VERSION "dbc-export 1 2026.26.6.5"

NS_ :

BS_:

BU_: ADSP APB APP APS APSB BB BMS CC CMP CMPD CP DAS DI DIF DIR DPB EPAS3P EPAS3S EPASTP EPASTS EPBL EPBR ESP EVSE FC GTW HCML HCMR HVP IBST ICR IDB LS OCS1P ODIN PARK PCS PCS2 PLG PM PMF PMR PNCD PTC RADC RCM RCM2 RCM3 RCU SCCM SCM SCS SDCR TAS TCU TCU2 TPMS TRCM UDS UI UIS UMC USM V2G VC VCBATT VCBATT0 VCBATT1 VCBATT2 VCCC VCFRONT VCFRONT1 VCFRONT2 VCLEFT VCRIGHT VCSEAT2L VCSEAT2R VCSEC VEH

BO_ 854 DIF_alertMatrix: 8 DIF
 SG_ DIF_matrixIndex M : 0|4@1+ (1,0) [0|15] "" Vector__XXX
 SG_ DIF_a001_hwPhaseAgateDrive m0 : 4|1@1+ (1,0) [0|1] "" Vector__XXX
 SG_ DIF_a002_hwPhaseBgateDrive m0 : 5|1@1+ (1,0) [0|1] "" Vector__XXX
 SG_ DIF_a003_hwPhaseCgateDrive m0 : 6|1@1+ (1,0) [0|1] "" Vector__XXX
 SG_ DIF_a004_hwPhaseApeak m0 : 7|1@1+ (1,0) [0|1] "" Vector__XXX
 SG_ DIF_a005_hwPhaseBpeak m0 : 8|1@1+ (1,0) [0|1] "" Vector__XXX
 SG_ DIF_a006_hwPhaseCpeak m0 : 9|1@1+ (1,0) [0|1] "" Vector__XXX
 SG_ DIF_a007_statorAnomalyDetected m0 : 10|1@1+ (1,0) [0|1] "" Vector__XXX
 SG_ DIF_a008_hwEncoderA m0 : 11|1@1+ (1,0) [0|1] "" Vector__XXX
 SG_ DIF_a009_hwEncoderB m0 : 12|1@1+ (1,0) [0|1] "" Vector__XXX
 SG_ DIF_a010_unintendedReset m0 : 13|1@1+ (1,0) [0|1] "" Vector__XXX
 SG_ DIF_a011_swPowerStageNotReady m0 : 14|1@1+ (1,0) [0|1] "" Vector__XXX
 SG_ DIF_a012_hvilNotClosed m0 : 15|1@1+ (1,0) [0|1] "" Vector__XXX
 SG_ DIF_a013_eccError m0 : 16|1@1+ (1,0) [0|1] "" Vector__XXX
 SG_ DIF_a014_activeDamping m0 : 17|1@1+ (1,0) [0|1] "" Vector__XXX
 SG_ DIF_a015_mechSafeStateAnomaly m0 : 18|1@1+ (1,0) [0|1] "" Vector__XXX
 SG_ DIF_a016_safeStateApplied m0 : 19|1@1+ (1,0) [0|1] "" Vector__XXX
 SG_ DIF_a017_hwPedalMonitor m0 : 20|1@1+ (1,0) [0|1] "" Vector__XXX
 SG_ DIF_a018_hwLVSupplyUV m0 : 21|1@1+ (1,0) [0|1] "" Vector__XXX
 SG_ DIF_a020_hwMotorEncoder m0 : 23|1@1+ (1,0) [0|1] "" Vector__XXX
 SG_ DIF_a021_hwBusOV m0 : 24|1@1+ (1,0) [0|1] "" Vector__XXX
 SG_ DIF_a022_hw5vSupplyUV m0 : 25|1@1+ (1,0) [0|1] "" Vector__XXX
 SG_ DIF_a024_selfTest m0 : 27|1@1+ (1,0) [0|1] "" Vector__XXX
 SG_ DIF_a025_phaseApeak m0 : 28|1@1+ (1,0) [0|1] "" Vector__XXX
 SG_ DIF_a026_phaseBpeak m0 : 29|1@1+ (1,0) [0|1] "" Vector__XXX
 SG_ DIF_a027_phaseCpeak m0 : 30|1@1+ (1,0) [0|1] "" Vector__XXX
 SG_ DIF_a028_phaseArms m0 : 31|1@1+ (1,0) [0|1] "" Vector__XXX
 SG_ DIF_a029_phaseBrms m0 : 32|1@1+ (1,0) [0|1] "" Vector__XXX
 SG_ DIF_a030_phaseCrms m0 : 33|1@1+ (1,0) [0|1] "" Vector__XXX
 SG_ DIF_a031_phaseAcurrentOffset m0 : 34|1@1+ (1,0) [0|1] "" Vector__XXX
 SG_ DIF_a032_phaseBcurrentOffset m0 : 35|1@1+ (1,0) [0|1] "" Vector__XXX
 SG_ DIF_a033_phaseAcurrentSensor m0 : 36|1@1+ (1,0) [0|1] "" Vector__XXX
 SG_ DIF_a034_phaseBcurrentSensor m0 : 37|1@1+ (1,0) [0|1] "" Vector__XXX
 SG_ DIF_a035_phaseCurrentBalance m0 : 38|1@1+ (1,0) [0|1] "" Vector__XXX
 SG_ DIF_a036_busOV m0 : 39|1@1+ (1,0) [0|1] "" Vector__XXX
 SG_ DIF_a037_busUV m0 : 40|1@1+ (1,0) [0|1] "" Vector__XXX
 SG_ DIF_a038_busVsensor m0 : 41|1@1+ (1,0) [0|1] "" Vector__XXX
 SG_ DIF_a039_exceptionUndefinedInstr m0 : 42|1@1+ (1,0) [0|1] "" Vector__XXX
 SG_ DIF_a040_difMIA m0 : 43|1@1+ (1,0) [0|1] "" Vector__XXX
 SG_ DIF_a041_sdcMIA m0 : 44|1@1+ (1,0) [0|1] "" Vector__XXX
 SG_ DIF_a042_inletSensor m0 : 45|1@1+ (1,0) [0|1] "" Vector__XXX
 SG_ DIF_a043_outletOT m0 : 46|1@1+ (1,0) [0|1] "" Vector__XXX
 SG_ DIF_a044_outletUT m0 : 47|1@1+ (1,0) [0|1] "" Vector__XXX
 SG_ DIF_a045_outletSensor m0 : 48|1@1+ (1,0) [0|1] "" Vector__XXX
 SG_ DIF_a046_statorOT m0 : 49|1@1+ (1,0) [0|1] "" Vector__XXX
 SG_ DIF_a047_statorSensor1 m0 : 50|1@1+ (1,0) [0|1] "" Vector__XXX
 SG_ DIF_a048_statorSensor2 m0 : 51|1@1+ (1,0) [0|1] "" Vector__XXX
 SG_ DIF_a049_statorSensorDiff m0 : 52|1@1+ (1,0) [0|1] "" Vector__XXX
 SG_ DIF_a050_noStatorSensor m0 : 53|1@1+ (1,0) [0|1] "" Vector__XXX
 SG_ DIF_a052_dirMIA m0 : 55|1@1+ (1,0) [0|1] "" Vector__XXX
 SG_ DIF_a053_unexpectedLatchState m0 : 56|1@1+ (1,0) [0|1] "" Vector__XXX
 SG_ DIF_a054_driveInverterOT m0 : 57|1@1+ (1,0) [0|1] "" Vector__XXX
 SG_ DIF_a055_trqCrossCheck m0 : 58|1@1+ (1,0) [0|1] "" Vector__XXX
 SG_ DIF_a056_ambientOT m0 : 59|1@1+ (1,0) [0|1] "" Vector__XXX
 SG_ DIF_a057_ambientUT m0 : 60|1@1+ (1,0) [0|1] "" Vector__XXX
 SG_ DIF_a058_ambientSensor m0 : 61|1@1+ (1,0) [0|1] "" Vector__XXX
 SG_ DIF_a059_heatsinkOT m0 : 62|1@1+ (1,0) [0|1] "" Vector__XXX
 SG_ DIF_a060_heatsinkUT m0 : 63|1@1+ (1,0) [0|1] "" Vector__XXX
 SG_ DIF_a061_heatsinkSensor m1 : 4|1@1+ (1,0) [0|1] "" Vector__XXX
 SG_ DIF_a062_systemLimpMode m1 : 5|1@1+ (1,0) [0|1] "" Vector__XXX
 SG_ DIF_a063_bbMIA m1 : 6|1@1+ (1,0) [0|1] "" Vector__XXX
 SG_ DIF_a064_torqueIntervention m1 : 7|1@1+ (1,0) [0|1] "" Vector__XXX
 SG_ DIF_a065_canHardwareBusB m1 : 8|1@1+ (1,0) [0|1] "" Vector__XXX
 SG_ DIF_a066_canDataBusB m1 : 9|1@1+ (1,0) [0|1] "" Vector__XXX
 SG_ DIF_a067_canOverrunBusB m1 : 10|1@1+ (1,0) [0|1] "" Vector__XXX
 SG_ DIF_a069_rotorTempLimit m1 : 12|1@1+ (1,0) [0|1] "" Vector__XXX
 SG_ DIF_a070_udsTransactionInitiated m1 : 13|1@1+ (1,0) [0|1] "" Vector__XXX
 SG_ DIF_a071_busDisconnected m1 : 14|1@1+ (1,0) [0|1] "" Vector__XXX
 SG_ DIF_a072_gateDriveFaultCounter m1 : 15|1@1+ (1,0) [0|1] "" Vector__XXX
 SG_ DIF_a073_motorSpeed m1 : 16|1@1+ (1,0) [0|1] "" Vector__XXX
 SG_ DIF_a074_motorEncoder m1 : 17|1@1+ (1,0) [0|1] "" Vector__XXX
 SG_ DIF_a075_motorSpeedMismatch m1 : 18|1@1+ (1,0) [0|1] "" Vector__XXX
 SG_ DIF_a076_lvSupplyOV m1 : 19|1@1+ (1,0) [0|1] "" Vector__XXX
 SG_ DIF_a077_lvSupplyUV m1 : 20|1@1+ (1,0) [0|1] "" Vector__XXX
 SG_ DIF_a078_adcRefLow m1 : 21|1@1+ (1,0) [0|1] "" Vector__XXX
 SG_ DIF_a079_adcRefHigh m1 : 22|1@1+ (1,0) [0|1] "" Vector__XXX
 SG_ DIF_a084_eccTestData0 m1 : 27|1@1+ (1,0) [0|1] "" Vector__XXX
 SG_ DIF_d085_driveInverterBoardFailu m1 : 28|1@1+ (1,0) [0|1] "" Vector__XXX
 SG_ DIF_a086_activeDischargeOn m1 : 29|1@1+ (1,0) [0|1] "" Vector__XXX
 SG_ DIF_a087_gtwMIA m1 : 30|1@1+ (1,0) [0|1] "" Vector__XXX
 SG_ DIF_a088_uiMIA m1 : 31|1@1+ (1,0) [0|1] "" Vector__XXX
 SG_ DIF_d089_invalidTorqueCommand m1 : 32|1@1+ (1,0) [0|1] "" Vector__XXX
 SG_ DIF_a090_pmMIA m1 : 33|1@1+ (1,0) [0|1] "" Vector__XXX
 SG_ DIF_a091_espMIA m1 : 34|1@1+ (1,0) [0|1] "" Vector__XXX
 SG_ DIF_a092_bmsMIA m1 : 35|1@1+ (1,0) [0|1] "" Vector__XXX
 SG_ DIF_a093_canHardwareBusA m1 : 36|1@1+ (1,0) [0|1] "" Vector__XXX
 SG_ DIF_a094_canDataBusA m1 : 37|1@1+ (1,0) [0|1] "" Vector__XXX
 SG_ DIF_a095_canOverrunBusA m1 : 38|1@1+ (1,0) [0|1] "" Vector__XXX
 SG_ DIF_a096_memoryError m1 : 39|1@1+ (1,0) [0|1] "" Vector__XXX
 SG_ DIF_a097_eepromError m1 : 40|1@1+ (1,0) [0|1] "" Vector__XXX
 SG_ DIF_a098_intTimeTooLong m1 : 41|1@1+ (1,0) [0|1] "" Vector__XXX
 SG_ DIF_a099_threadOverrun m1 : 42|1@1+ (1,0) [0|1] "" Vector__XXX
 SG_ DIF_a100_assertion m1 : 43|1@1+ (1,0) [0|1] "" Vector__XXX
 SG_ DIF_a101_eccTestData1 m1 : 44|1@1+ (1,0) [0|1] "" Vector__XXX
 SG_ DIF_a102_exceptionPrefetchAbort m1 : 45|1@1+ (1,0) [0|1] "" Vector__XXX
 SG_ DIF_a103_lowFlow m1 : 46|1@1+ (1,0) [0|1] "" Vector__XXX
 SG_ DIF_d104_resetUnintended m1 : 47|1@1+ (1,0) [0|1] "" Vector__XXX
 SG_ DIF_d105_busVoltageSensorIssue m1 : 48|1@1+ (1,0) [0|1] "" Vector__XXX
 SG_ DIF_a106_idleTaskStarving m1 : 49|1@1+ (1,0) [0|1] "" Vector__XXX
 SG_ DIF_a107_fpgaError m1 : 50|1@1+ (1,0) [0|1] "" Vector__XXX
 SG_ DIF_a108_stateTrans m1 : 51|1@1+ (1,0) [0|1] "" Vector__XXX
 SG_ DIF_a109_ahbWriteError m1 : 52|1@1+ (1,0) [0|1] "" Vector__XXX
 SG_ DIF_a110_brakeMIA m1 : 53|1@1+ (1,0) [0|1] "" Vector__XXX
 SG_ DIF_a111_badPhaseSensorCalib m1 : 54|1@1+ (1,0) [0|1] "" Vector__XXX
 SG_ DIF_a112_noPhaseCurrent m1 : 55|1@1+ (1,0) [0|1] "" Vector__XXX
 SG_ DIF_a113_noFuncHeatsinkSensor m1 : 56|1@1+ (1,0) [0|1] "" Vector__XXX
 SG_ DIF_a114_exceptionDataAbort m1 : 57|1@1+ (1,0) [0|1] "" Vector__XXX
 SG_ DIF_a115_exceptionDataAbort2 m1 : 58|1@1+ (1,0) [0|1] "" Vector__XXX
 SG_ DIF_a116_highSpeedWearCounter m1 : 59|1@1+ (1,0) [0|1] "" Vector__XXX
 SG_ DIF_a117_diMIA m1 : 60|1@1+ (1,0) [0|1] "" Vector__XXX
 SG_ DIF_d118_oilPumpCommsLost m1 : 61|1@1+ (1,0) [0|1] "" Vector__XXX
 SG_ DIF_a119_hvpMIA m1 : 62|1@1+ (1,0) [0|1] "" Vector__XXX
 SG_ DIF_a120_hvlinkMIA m1 : 63|1@1+ (1,0) [0|1] "" Vector__XXX
 SG_ DIF_a121_motorControlRegulation m2 : 4|1@1+ (1,0) [0|1] "" Vector__XXX
 SG_ DIF_a122_highStackUsage m2 : 5|1@1+ (1,0) [0|1] "" Vector__XXX
 SG_ DIF_a123_lossMotorControl m2 : 6|1@1+ (1,0) [0|1] "" Vector__XXX
 SG_ DIF_d124_oilPumpServiceRequired m2 : 7|1@1+ (1,0) [0|1] "" Vector__XXX
 SG_ DIF_d125_currentSensorIssue m2 : 8|1@1+ (1,0) [0|1] "" Vector__XXX
 SG_ DIF_a126_limpMode m2 : 9|1@1+ (1,0) [0|1] "" Vector__XXX
 SG_ DIF_a127_gracefulPowerOff m2 : 10|1@1+ (1,0) [0|1] "" Vector__XXX
 SG_ DIF_a128_fpgaVersionMismatch m2 : 11|1@1+ (1,0) [0|1] "" Vector__XXX
 SG_ DIF_d129_oilPumpIssue m2 : 12|1@1+ (1,0) [0|1] "" Vector__XXX
 SG_ DIF_d130_positionSensorIssue m2 : 13|1@1+ (1,0) [0|1] "" Vector__XXX
 SG_ DIF_d131_currentSensorOffset m2 : 14|1@1+ (1,0) [0|1] "" Vector__XXX
 SG_ DIF_d132_busUVIssue m2 : 15|1@1+ (1,0) [0|1] "" Vector__XXX
 SG_ DIF_a133_capacitorOT m2 : 16|1@1+ (1,0) [0|1] "" Vector__XXX
 SG_ DIF_a134_wheelSpeedIrrational m2 : 17|1@1+ (1,0) [0|1] "" Vector__XXX
 SG_ DIF_d135_rotatedStator m2 : 18|1@1+ (1,0) [0|1] "" Vector__XXX
 SG_ DIF_a136_spiError m2 : 19|1@1+ (1,0) [0|1] "" Vector__XXX
 SG_ DIF_d137_currentSensorOutOfRange m2 : 20|1@1+ (1,0) [0|1] "" Vector__XXX
 SG_ DIF_d138_inverterLVPowerSupplyLo m2 : 21|1@1+ (1,0) [0|1] "" Vector__XXX
 SG_ DIF_d141_coolingSystemIssue m2 : 24|1@1+ (1,0) [0|1] "" Vector__XXX
 SG_ DIF_a142_highLashAngle m2 : 25|1@1+ (1,0) [0|1] "" Vector__XXX
 SG_ DIF_d143_wheelSpeedCorrelationIs m2 : 26|1@1+ (1,0) [0|1] "" Vector__XXX
 SG_ DIF_a144_configMismatch m2 : 27|1@1+ (1,0) [0|1] "" Vector__XXX
 SG_ DIF_a147_highTorqueWearLimit m2 : 30|1@1+ (1,0) [0|1] "" Vector__XXX
 SG_ DIF_a148_burnInCycleEnded m2 : 31|1@1+ (1,0) [0|1] "" Vector__XXX
 SG_ DIF_a149_oilPumpFailure m2 : 32|1@1+ (1,0) [0|1] "" Vector__XXX
 SG_ DIF_a150_busVD m2 : 33|1@1+ (1,0) [0|1] "" Vector__XXX
 SG_ DIF_a151_shockTorqueLimiter m2 : 34|1@1+ (1,0) [0|1] "" Vector__XXX
 SG_ DIF_a152_linError m2 : 35|1@1+ (1,0) [0|1] "" Vector__XXX
 SG_ DIF_a153_oilPumpDiagnostics m2 : 36|1@1+ (1,0) [0|1] "" Vector__XXX
 SG_ DIF_a154_resolver m2 : 37|1@1+ (1,0) [0|1] "" Vector__XXX
 SG_ DIF_a155_vcfrontMIA m2 : 38|1@1+ (1,0) [0|1] "" Vector__XXX
 SG_ DIF_a156_currentObserver m2 : 39|1@1+ (1,0) [0|1] "" Vector__XXX
 SG_ DIF_a157_rcmMIA m2 : 40|1@1+ (1,0) [0|1] "" Vector__XXX
 SG_ DIF_a158_ibstMIA m2 : 41|1@1+ (1,0) [0|1] "" Vector__XXX
 SG_ DIF_a160_busVoltageAnomaly m2 : 43|1@1+ (1,0) [0|1] "" Vector__XXX
 SG_ DIF_a161_epas3pMIA m2 : 44|1@1+ (1,0) [0|1] "" Vector__XXX
 SG_ DIF_a162_endOfLifetimeBurnIn m2 : 45|1@1+ (1,0) [0|1] "" Vector__XXX
 SG_ DIF_d163_recoverableOvercurrent m2 : 46|1@1+ (1,0) [0|1] "" Vector__XXX
 SG_ DIF_d164_firmwareConfigMismatch m2 : 47|1@1+ (1,0) [0|1] "" Vector__XXX
 SG_ DIF_d165_statorOverTemperature m2 : 48|1@1+ (1,0) [0|1] "" Vector__XXX
 SG_ DIF_d166_rotorOverTemperature m2 : 49|1@1+ (1,0) [0|1] "" Vector__XXX
 SG_ DIF_d167_tempSensorIssue m2 : 50|1@1+ (1,0) [0|1] "" Vector__XXX
 SG_ DIF_d168_clutchPerformance m2 : 51|1@1+ (1,0) [0|1] "" Vector__XXX
 SG_ DIF_d169_clutchPosition m2 : 52|1@1+ (1,0) [0|1] "" Vector__XXX
 SG_ DIF_d170_clutchFailure m2 : 53|1@1+ (1,0) [0|1] "" Vector__XXX
 SG_ DIF_a172_statorOilTempOT m2 : 55|1@1+ (1,0) [0|1] "" Vector__XXX
 SG_ DIF_a173_ascFdbkDiagnostic m2 : 56|1@1+ (1,0) [0|1] "" Vector__XXX
 SG_ DIF_a174_unitMayNotRestart m2 : 57|1@1+ (1,0) [0|1] "" Vector__XXX
 SG_ DIF_a176_safetyICFault m2 : 59|1@1+ (1,0) [0|1] "" Vector__XXX
 SG_ DIF_a177_fluxReferenceCorrected m2 : 60|1@1+ (1,0) [0|1] "" Vector__XXX
 SG_ DIF_a202_excessHeatUnavailable m3 : 25|1@1+ (1,0) [0|1] "" Vector__XXX
 SG_ DIF_a225_tmpEstPlausibility m3 : 48|1@1+ (1,0) [0|1] "" Vector__XXX
 SG_ DIF_a229_busVsensorOverCAN m3 : 52|1@1+ (1,0) [0|1] "" Vector__XXX
 SG_ DIF_a233_diMsgMissed m3 : 56|1@1+ (1,0) [0|1] "" Vector__XXX
 SG_ DIF_a234_pcsMIA m3 : 57|1@1+ (1,0) [0|1] "" Vector__XXX
 SG_ DIF_a236_tasMIA m3 : 59|1@1+ (1,0) [0|1] "" Vector__XXX
 SG_ DIF_a240_clearFusesRoutine m3 : 63|1@1+ (1,0) [0|1] "" Vector__XXX
 SG_ DIF_a241_systemThermallyLimited m4 : 4|1@1+ (1,0) [0|1] "" Vector__XXX
 SG_ DIF_a242_spinDownLearning m4 : 5|1@1+ (1,0) [0|1] "" Vector__XXX
 SG_ DIF_a243_ecuLogAvailable m4 : 6|1@1+ (1,0) [0|1] "" Vector__XXX
 SG_ DIF_a244_mechSafeStateApplied m4 : 7|1@1+ (1,0) [0|1] "" Vector__XXX
 SG_ DIF_a245_mechSafeStatePreWarn m4 : 8|1@1+ (1,0) [0|1] "" Vector__XXX
 SG_ DIF_a246_recoveryAtSpeedError m4 : 9|1@1+ (1,0) [0|1] "" Vector__XXX
 SG_ DIF_a247_rotorOffsetError m4 : 10|1@1+ (1,0) [0|1] "" Vector__XXX
 SG_ DIF_a249_highStatorTempFromResis m4 : 12|1@1+ (1,0) [0|1] "" Vector__XXX
 SG_ DIF_a250_preregulatorRail m4 : 13|1@1+ (1,0) [0|1] "" Vector__XXX
 SG_ DIF_a251_oilPumpService m4 : 14|1@1+ (1,0) [0|1] "" Vector__XXX
 SG_ DIF_a252_currentCoreFallback m4 : 15|1@1+ (1,0) [0|1] "" Vector__XXX
 SG_ DIF_a253_lvBoostedRail m4 : 16|1@1+ (1,0) [0|1] "" Vector__XXX
 SG_ DIF_a254_activeDischargeRail m4 : 17|1@1+ (1,0) [0|1] "" Vector__XXX
 SG_ DIF_a255_currentGainFallback m4 : 18|1@1+ (1,0) [0|1] "" Vector__XXX

BO_ 1879 DIF_debug: 8 DIF
 SG_ DIF_debugSelector M : 0|8@1+ (1,0) [0|255] "" Vector__XXX
 SG_ DIF_motorIA m32 : 8|16@1+ (0.1,0) [0|6553.5] "A" Vector__XXX
 SG_ DIF_motorIB m32 : 24|16@1+ (0.1,0) [0|6553.5] "A" Vector__XXX
 SG_ DIF_motorIC m32 : 40|16@1+ (0.1,0) [0|6553.5] "A" Vector__XXX
 SG_ DIF_statorIDref m33 : 8|16@1- (0.1,0) [-3276.8|3276.7] "A" Vector__XXX
 SG_ DIF_statorIDfdb m33 : 24|16@1- (0.1,0) [-3276.8|3276.7] "A" Vector__XXX
 SG_ DIF_torquePerAmp m33 : 40|16@1+ (0.0001,0) [0|6.5535] "Nm/A" Vector__XXX
 SG_ DIF_rsScale m34 : 8|8@1+ (0.01,0) [0|2.55] "scale" Vector__XXX
 SG_ DIF_statorIQref m34 : 16|16@1- (0.1,0) [-3276.8|3276.7] "A" Vector__XXX
 SG_ DIF_statorIQfdb m34 : 32|16@1- (0.1,0) [-3276.8|3276.7] "A" Vector__XXX
 SG_ DIF_motorV m34 : 48|16@1+ (2.0e-05,0) [0|1.3107] "mindex" Vector__XXX
 SG_ DIF_tqScaleDifferential m35 : 8|8@1+ (0.4,0) [0|102] "%" Vector__XXX
 SG_ DIF_statorFluxRef m35 : 16|16@1+ (0.0001,0) [0|6.5535] "Wb" Vector__XXX
 SG_ DIF_statorFluxFdb m35 : 32|16@1+ (0.0001,0) [0|6.5535] "Wb" Vector__XXX
 SG_ DIF_lmScale m36 : 8|8@1+ (0.004,0) [0|1.02] "scale" Vector__XXX
 SG_ DIF_statorVQ m36 : 16|16@1- (4.0e-05,0) [-1.31072|1.31068] "mindex" Vector__XXX
 SG_ DIF_statorVD m36 : 32|16@1- (4.0e-05,0) [-1.31072|1.31068] "mindex" Vector__XXX
 SG_ DIF_peakFlux m36 : 48|16@1+ (0.0001,0) [0|6.5535] "Wb" Vector__XXX
 SG_ DIF_gainScale m37 : 8|8@1+ (0.01,0) [0|2.55] "scale" Vector__XXX
 SG_ DIF_usmState m38 : 12|3@1+ (1,0) [0|7] "" Vector__XXX
 SG_ DIF_peakIQref m38 : 16|16@1+ (0.1,0) [0|6553.5] "A" Vector__XXX
 SG_ DIF_motorIAavg m38 : 32|16@1- (0.1,0) [-3276.8|3276.7] "A" Vector__XXX
 SG_ DIF_motorIBavg m38 : 48|16@1- (0.1,0) [-3276.8|3276.7] "A" Vector__XXX
 SG_ DIF_tqSatThermal m39 : 8|8@1+ (0.4,0) [0|102] "%" Vector__XXX
 SG_ DIF_tqSatMotorVoltage m39 : 32|8@1+ (0.4,0) [0|102] "%" Vector__XXX
 SG_ DIF_tqSatMotorCurrent m39 : 40|8@1+ (0.4,0) [0|102] "%" Vector__XXX
 SG_ DIF_tcMaxRequest m40 : 16|8@1+ (5,0) [0|1275] "Nm" Vector__XXX
 SG_ DIF_tcMinRequest m40 : 24|8@1+ (5,0) [0|1275] "Nm" Vector__XXX
 SG_ DIF_tqScaleMaxMotorSpeed m40 : 48|8@1+ (0.4,0) [0|102] "%" Vector__XXX
 SG_ DIF_wasteCurrentLimit m41 : 32|16@1+ (0.1,0) [0|6553.5] "A" Vector__XXX
 SG_ DIF_llsScale m42 : 24|8@1+ (0.004,0) [0|1.02] "scale" Vector__XXX
 SG_ DIF_llrScale m42 : 32|8@1+ (0.015,0) [0|3.825] "scale" Vector__XXX
 SG_ DIF_oilPumpMotorSpeed m46 : 8|8@1+ (40,0) [0|10200] "RPM" Vector__XXX
 SG_ DIF_rotorFlux m47 : 16|16@1+ (0.0001,0) [0|6.5535] "Wb" Vector__XXX
 SG_ DIF_dcCableHeat m47 : 32|16@1+ (0.001,0) [0|65.535] "kA2s" Vector__XXX
 SG_ DIF_magnetTempEst m47 : 48|8@1+ (1,-40) [-40|215] "DegC" Vector__XXX
 SG_ DIF_resolverReady m48 : 40|1@1+ (1,0) [0|1] "" Vector__XXX
 SG_ DIF_resolverNoCarrier m48 : 41|1@1+ (1,0) [0|1] "" Vector__XXX
 SG_ DIF_resolverNoPhaseLock m48 : 42|1@1+ (1,0) [0|1] "" Vector__XXX
 SG_ DIF_resolverClaMIA m48 : 43|1@1+ (1,0) [0|1] "" Vector__XXX
 SG_ DIF_soptMaxCurrentMagSqrd m49 : 40|16@1+ (100,0) [0|6553500] "A2" Vector__XXX
 SG_ DIF_statorVDFiltered m63 : 16|16@1- (4.0e-05,0) [-1.31072|1.31068] "mindex" Vector__XXX
 SG_ DIF_statorVQFiltered m63 : 32|16@1- (4.0e-05,0) [-1.31072|1.31068] "mindex" Vector__XXX
 SG_ DIF_pwmState m63 : 48|2@1+ (1,0) [0|3] "" Vector__XXX
 SG_ DIF_dcCapTemp m64 : 8|8@1+ (1,-40) [-40|215] "DegC" Vector__XXX
 SG_ DIF_busbarTemp m64 : 16|8@1+ (1,-40) [-40|215] "DegC" Vector__XXX
 SG_ DIF_pcsTemp m64 : 24|8@1+ (1,-40) [-40|215] "DegC" Vector__XXX
 SG_ DIF_statorTemp1 m64 : 32|8@1+ (1,-40) [-40|215] "DegC" Vector__XXX
 SG_ DIF_statorTemp2 m64 : 40|8@1+ (1,-40) [-40|215] "DegC" Vector__XXX
 SG_ DIF_cpu10HzMin m66 : 8|8@1+ (0.4,0) [0|102] "%" Vector__XXX
 SG_ DIF_cpu10HzAvg m66 : 16|8@1+ (0.4,0) [0|102] "%" Vector__XXX
 SG_ DIF_cpu100HzMin m66 : 24|8@1+ (0.4,0) [0|102] "%" Vector__XXX
 SG_ DIF_cpu100HzAvg m66 : 32|8@1+ (0.4,0) [0|102] "%" Vector__XXX
 SG_ DIF_cpu10msMin m66 : 40|8@1+ (0.4,0) [0|102] "%" Vector__XXX
 SG_ DIF_cpu1kHzMin m67 : 8|8@1+ (0.4,0) [0|102] "%" Vector__XXX
 SG_ DIF_cpu1kHzAvg m67 : 16|8@1+ (0.4,0) [0|102] "%" Vector__XXX
 SG_ DIF_cpu20kHzMin m67 : 24|8@1+ (0.4,0) [0|102] "%" Vector__XXX
 SG_ DIF_cpu20kHzAvg m67 : 32|8@1+ (0.4,0) [0|102] "%" Vector__XXX
 SG_ DIF_hwFaultCount m69 : 8|4@1+ (1,0) [0|15] "" Vector__XXX
 SG_ DIF_driveUnitOdometer m69 : 32|32@1+ (10,0) [0|42949672950] "rev" Vector__XXX
 SG_ DIF_phaseOutBusbarTemp m70 : 8|8@1+ (1,-40) [-39|215] "DegC" Vector__XXX
 SG_ DIF_phaseOutBusbarWeldTemp m70 : 16|8@1+ (1,-40) [-39|215] "DegC" Vector__XXX
 SG_ DIF_phaseOutLugTemp m70 : 24|8@1+ (1,-40) [-39|215] "DegC" Vector__XXX
 SG_ DIF_dcLinkCapTemp m70 : 32|8@1+ (1,-40) [-39|215] "DegC" Vector__XXX
 SG_ DIF_hvDcCableTemp m70 : 40|8@1+ (1,-40) [-39|215] "DegC" Vector__XXX
 SG_ DIF_negDcBusbarTemp m70 : 48|8@1+ (1,-40) [-39|215] "DegC" Vector__XXX
 SG_ DIF_posDcBusbarTemp m70 : 56|8@1+ (1,-40) [-39|215] "DegC" Vector__XXX
 SG_ DIF_statorEndWindingTemp m72 : 8|8@1+ (1,-40) [-39|215] "DegC" Vector__XXX
 SG_ DIF_rotorMaxMagnetTemp m72 : 16|8@1+ (1,-40) [-39|215] "DegC" Vector__XXX
 SG_ DIF_lightSenseV m72 : 24|6@1+ (0.1,0) [0|3.3] "V" Vector__XXX
 SG_ DIF_pyroSenseV m72 : 30|8@1+ (0.02,0) [0|3.3] "V" Vector__XXX
 SG_ DIF_statorSlotWindingTemp m72 : 46|8@1+ (1,-40) [-39|215] "DegC" Vector__XXX
 SG_ DIF_intervalMaxHvBusV m72 : 54|10@1+ (1,0) [0|1023] "V" Vector__XXX
 SG_ DIF_cpu1HzMin m128 : 8|8@1+ (0.4,0) [0|102] "%" Vector__XXX
 SG_ DIF_cpu1HzAvg m128 : 16|8@1+ (0.4,0) [0|102] "%" Vector__XXX
 SG_ DIF_cpuIDWord0 m131 : 16|16@1+ (1,0) [0|65535] "" Vector__XXX
 SG_ DIF_cpuIDWord1 m132 : 16|16@1+ (1,0) [0|65535] "" Vector__XXX
 SG_ DIF_cpuIDWord2 m132 : 32|16@1+ (1,0) [0|65535] "" Vector__XXX
 SG_ DIF_cpuIDWord3 m132 : 48|16@1+ (1,0) [0|65535] "" Vector__XXX

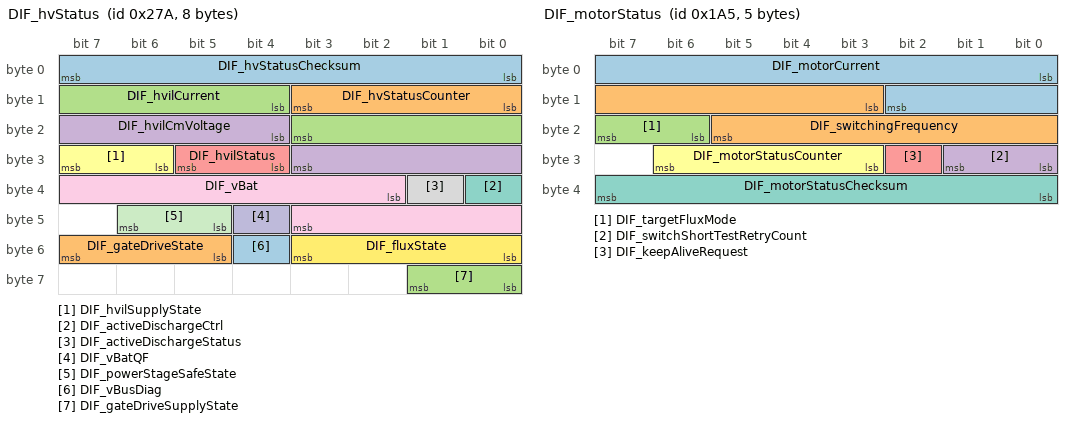
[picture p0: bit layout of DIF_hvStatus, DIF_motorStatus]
BO_ 634 DIF_hvStatus: 8 DIF
 SG_ DIF_hvStatusChecksum : 0|8@1+ (1,0) [0|255] "" Vector__XXX
 SG_ DIF_hvStatusCounter : 8|4@1+ (1,0) [0|15] "" Vector__XXX
 SG_ DIF_hvilCurrent : 12|8@1+ (0.1,0) [0|25.5] "mA" Vector__XXX
 SG_ DIF_hvilCmVoltage : 20|8@1+ (0.08,0) [0|20.4] "V" Vector__XXX
 SG_ DIF_hvilStatus : 28|2@1+ (1,0) [0|2] "" Vector__XXX
 SG_ DIF_hvilSupplyState : 30|2@1+ (1,0) [0|3] "" Vector__XXX
 SG_ DIF_activeDischargeCtrl : 32|1@1+ (1,0) [0|1] "" Vector__XXX
 SG_ DIF_activeDischargeStatus : 33|1@1+ (1,0) [0|1] "" Vector__XXX
 SG_ DIF_vBat : 34|10@1+ (1,0) [0|1023] "V" Vector__XXX
 SG_ DIF_vBatQF : 44|1@1+ (1,0) [0|1] "" Vector__XXX
 SG_ DIF_powerStageSafeState : 45|2@1+ (1,0) [0|3] "" Vector__XXX
 SG_ DIF_fluxState : 48|4@1+ (1,0) [0|15] "" Vector__XXX
 SG_ DIF_vBusDiag : 52|1@1+ (1,0) [0|1] "" Vector__XXX
 SG_ DIF_gateDriveState : 53|3@1+ (1,0) [0|7] "" Vector__XXX
 SG_ DIF_gateDriveSupplyState : 56|2@1+ (1,0) [0|3] "" Vector__XXX

BO_ 1622 DIF_info: 8 DIF
 SG_ DIF_infoIndex M : 0|8@1+ (1,0) [0|255] "" Vector__XXX
 SG_ DIF_buildType m10 : 8|3@1+ (1,0) [0|7] "" Vector__XXX
 SG_ DIF_buildConfigurationId m10 : 16|16@1+ (1,0) [0|65535] "" Vector__XXX
 SG_ DIF_hardwareId m10 : 32|8@1+ (1,0) [0|252] "" Vector__XXX
 SG_ DIF_componentId m10 : 48|16@1+ (1,0) [0|65535] "" Vector__XXX
 SG_ DIF_pcbaId m11 : 16|8@1+ (1,0) [0|255] "" Vector__XXX
 SG_ DIF_assemblyId m11 : 24|8@1+ (1,0) [0|255] "" Vector__XXX
 SG_ DIF_usageId m11 : 32|16@1+ (1,0) [0|65535] "" Vector__XXX
 SG_ DIF_subUsageId m11 : 48|16@1+ (1,0) [0|65535] "" Vector__XXX
 SG_ DIF_motorType m12 : 8|6@1+ (1,0) [1|63] "" Vector__XXX
 SG_ DIF_siliconType m12 : 16|1@1+ (1,0) [0|1] "" Vector__XXX
 SG_ DIF_mechSafeStateType m12 : 24|2@1+ (1,0) [1|3] "" Vector__XXX
 SG_ DIF_applicationCrc m13 : 32|32@1+ (1,0) [0|4294967295] "" Vector__XXX
 SG_ DIF_oilPumpBuildType m16 : 8|3@1+ (1,0) [0|7] "" Vector__XXX
 SG_ DIF_oilPumpAppCrc m16 : 16|32@1+ (1,0) [0|4294967295] "" Vector__XXX
 SG_ DIF_FPGA_version m16 : 48|8@1+ (1,0) [0|254] "" Vector__XXX
 SG_ DIF_appGitHash m17 : 8|56@1+ (1,0) [0|7.20575940379e+16] "" Vector__XXX
 SG_ DIF_bootGitHash m18 : 8|56@1+ (1,0) [0|7.20575940379e+16] "" Vector__XXX
 SG_ DIF_platformTyp m19 : 8|8@1+ (1,0) [0|255] "" Vector__XXX
 SG_ DIF_infoBootLdUdsProtocolVersion m20 : 8|8@1+ (1,0) [0|255] "" Vector__XXX
 SG_ DIF_bootloaderCrc m20 : 32|32@1+ (1,0) [0|4294967295] "" Vector__XXX
 SG_ DIF_subcomponentGitHash m31 : 8|56@1+ (1,0) [0|7.20575940379e+16] "" Vector__XXX
 SG_ DIF_oilPumpPcbaId m33 : 8|8@1+ (1,0) [0|255] "" Vector__XXX
 SG_ DIF_oilPumpAssemblyId m33 : 16|8@1+ (1,0) [0|255] "" Vector__XXX
 SG_ DIF_oilPumpUsageId m33 : 24|16@1+ (1,0) [0|65535] "" Vector__XXX
 SG_ DIF_refRotorFlux m35 : 8|16@1+ (0.0001,0) [0|6.5535] "Wb" Vector__XXX
 SG_ DIF_refRotorOffset m35 : 24|12@1- (0.1,0) [-180|180] "deg" Vector__XXX
 SG_ DIF_speedWearTotal m36 : 8|8@1+ (0.4,0) [0|100] "%" Vector__XXX
 SG_ DIF_torqueWearTotal m36 : 24|8@1+ (0.02,0) [0|5.08] "1" Vector__XXX

BO_ 421 DIF_motorStatus: 5 DIF
 SG_ DIF_motorCurrent : 0|11@1+ (1,0) [0|2047] "A" Vector__XXX
 SG_ DIF_switchingFrequency : 11|11@1+ (0.01,0) [0|20] "kHz" Vector__XXX
 SG_ DIF_targetFluxMode : 22|2@1+ (1,0) [0|3] "" Vector__XXX
 SG_ DIF_switchShortTestRetryCount : 24|2@1+ (1,0) [0|3] "" Vector__XXX
 SG_ DIF_keepAliveRequest : 26|1@1+ (1,0) [0|1] "" Vector__XXX
 SG_ DIF_motorStatusCounter : 27|4@1+ (1,0) [0|15] "" Vector__XXX
 SG_ DIF_motorStatusChecksum : 32|8@1+ (1,0) [0|255] "" Vector__XXX

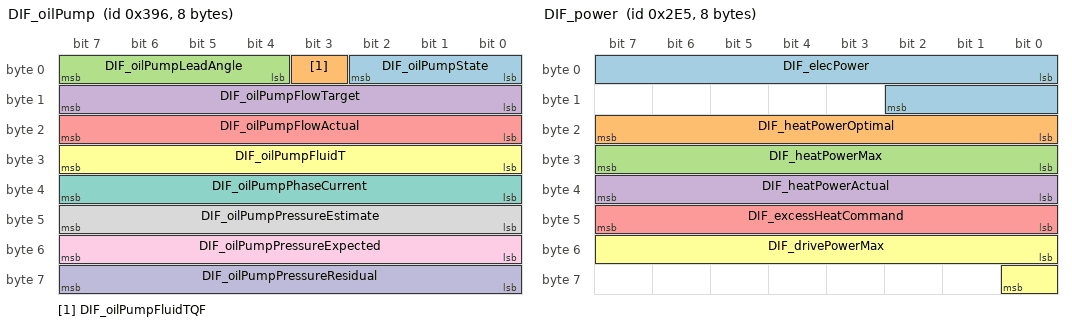
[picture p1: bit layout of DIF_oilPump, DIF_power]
BO_ 918 DIF_oilPump: 8 DIF
 SG_ DIF_oilPumpState : 0|3@1+ (1,0) [0|6] "" Vector__XXX
 SG_ DIF_oilPumpFluidTQF : 3|1@1+ (1,0) [0|1] "" Vector__XXX
 SG_ DIF_oilPumpLeadAngle : 4|4@1+ (1.875,0) [0|28.125] "degrees" Vector__XXX
 SG_ DIF_oilPumpFlowTarget : 8|8@1+ (0.1,0) [0|25.4] "LPM" Vector__XXX
 SG_ DIF_oilPumpFlowActual : 16|8@1+ (0.1,0) [0|25.4] "LPM" Vector__XXX
 SG_ DIF_oilPumpFluidT : 24|8@1+ (1,-40) [-40|214] "DegC" Vector__XXX
 SG_ DIF_oilPumpPhaseCurrent : 32|8@1+ (0.1,0) [0|25.4] "A" Vector__XXX
 SG_ DIF_oilPumpPressureEstimate : 40|8@1+ (2,0) [0|500] "kPa" Vector__XXX
 SG_ DIF_oilPumpPressureExpected : 48|8@1+ (2,0) [0|500] "kPa" Vector__XXX
 SG_ DIF_oilPumpPressureResidual : 56|8@1+ (4,-500) [-500|500] "kPa" Vector__XXX

BO_ 741 DIF_power: 8 DIF
 SG_ DIF_elecPower : 0|11@1- (0.5,0) [-500|500] "kW" Vector__XXX
 SG_ DIF_heatPowerOptimal : 16|8@1+ (0.08,0) [0|20] "kW" Vector__XXX
 SG_ DIF_heatPowerMax : 24|8@1+ (0.08,0) [0|20] "kW" Vector__XXX
 SG_ DIF_heatPowerActual : 32|8@1+ (0.08,0) [0|20] "kW" Vector__XXX
 SG_ DIF_excessHeatCommand : 40|8@1+ (0.08,0) [0|20] "kW" Vector__XXX
 SG_ DIF_drivePowerMax : 48|9@1+ (1,0) [0|400] "kW" Vector__XXX

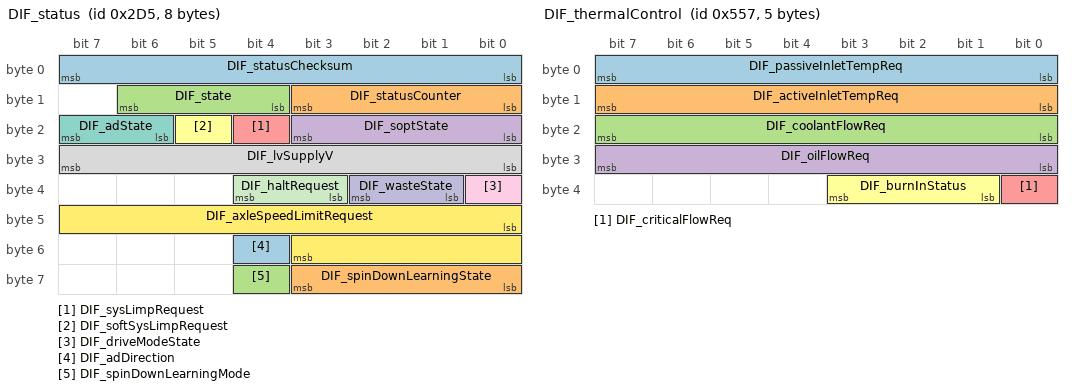
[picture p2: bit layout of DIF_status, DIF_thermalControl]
BO_ 725 DIF_status: 8 DIF
 SG_ DIF_statusChecksum : 0|8@1+ (1,0) [0|255] "" Vector__XXX
 SG_ DIF_statusCounter : 8|4@1+ (1,0) [0|15] "" Vector__XXX
 SG_ DIF_state : 12|3@1+ (1,0) [0|7] "" Vector__XXX
 SG_ DIF_soptState : 16|4@1+ (1,0) [0|15] "" Vector__XXX
 SG_ DIF_sysLimpRequest : 20|1@1+ (1,0) [0|1] "" Vector__XXX
 SG_ DIF_softSysLimpRequest : 21|1@1+ (1,0) [0|1] "" Vector__XXX
 SG_ DIF_adState : 22|2@1+ (1,0) [0|3] "" Vector__XXX
 SG_ DIF_lvSupplyV : 24|8@1+ (0.1,0) [0|25.5] "V" Vector__XXX
 SG_ DIF_driveModeState : 32|1@1+ (1,0) [0|1] "" Vector__XXX
 SG_ DIF_wasteState : 33|2@1+ (1,0) [0|3] "" Vector__XXX
 SG_ DIF_haltRequest : 35|2@1+ (1,0) [0|3] "" Vector__XXX
 SG_ DIF_axleSpeedLimitRequest : 40|12@1+ (1,40) [40|2750] "RPM" Vector__XXX
 SG_ DIF_adDirection : 52|1@1+ (1,0) [0|1] "" Vector__XXX
 SG_ DIF_spinDownLearningState : 56|4@1+ (1,0) [0|15] "" Vector__XXX
 SG_ DIF_spinDownLearningMode : 60|1@1+ (1,0) [0|1] "" Vector__XXX

BO_ 886 DIF_temperature: 8 DIF
 SG_ DIF_tempIndex M : 0|3@1+ (1,0) [0|7] "" Vector__XXX
 SG_ DIF_inverterTQF m0 : 3|2@1+ (1,0) [0|3] "" Vector__XXX
 SG_ DIF_pcbT m0 : 8|8@1+ (1,-40) [-39|215] "DegC" Vector__XXX
 SG_ DIF_inverterT m0 : 16|8@1+ (1,-40) [-40|215] "DegC" Vector__XXX
 SG_ DIF_statorT m0 : 24|8@1+ (1,-40) [-39|215] "DegC" Vector__XXX
 SG_ DIF_dcCapT m0 : 32|8@1+ (1,-40) [-39|215] "DegC" Vector__XXX
 SG_ DIF_heatsinkT m0 : 40|8@1+ (1,-40) [-39|215] "DegC" Vector__XXX
 SG_ DIF_inverterTpct m0 : 48|8@1+ (0.4,0) [0|100] "%" Vector__XXX
 SG_ DIF_statorTpct m0 : 56|8@1+ (0.4,0) [0|100] "%" Vector__XXX
 SG_ DIF_fluidInTemp m2 : 8|8@1+ (1,-40) [-39|215] "DegC" Vector__XXX
 SG_ DIF_normalFetBurnIn m2 : 16|16@1+ (0.00763,0) [0|500] "Hours" Vector__XXX
 SG_ DIF_additionalFetBurnIn m2 : 32|16@1+ (0.00763,0) [0|500] "Hours" Vector__XXX
 SG_ DIF_currentWeibullMiles m3 : 3|16@1+ (8,0) [0|500000] "miles" Vector__XXX
 SG_ DIF_endOfServiceWeibullMiles m3 : 19|16@1+ (8,0) [0|500000] "miles" Vector__XXX
 SG_ DIF_burnInDamageRatio m3 : 35|9@1+ (0.01,0) [0|5] "1" Vector__XXX
 SG_ DIF_inverterSensorEst m3 : 44|8@1+ (1,-40) [-40|120] "C" Vector__XXX
 SG_ DIF_inverterHS1Est m3 : 52|8@1+ (1,-40) [-40|120] "C" Vector__XXX
 SG_ DIF_initialBurnInVehicleOdometer m4 : 8|32@1+ (0.001,0) [0|4294967.294] "km" Vector__XXX
 SG_ DIF_inverterHS2Est m4 : 40|8@1+ (1,-40) [-40|120] "C" Vector__XXX
 SG_ DIF_inverterInletEst m4 : 48|8@1+ (1,-40) [-40|120] "C" Vector__XXX
 SG_ DIF_statorHousingTemp m4 : 56|8@1+ (1,-40) [-39|215] "DegC" Vector__XXX

BO_ 1367 DIF_thermalControl: 5 DIF
 SG_ DIF_passiveInletTempReq : 0|8@1+ (1,-40) [-40|215] "DegC" Vector__XXX
 SG_ DIF_activeInletTempReq : 8|8@1+ (1,-40) [-40|215] "DegC" Vector__XXX
 SG_ DIF_coolantFlowReq : 16|8@1+ (0.2,0) [0|50] "LPM" Vector__XXX
 SG_ DIF_oilFlowReq : 24|8@1+ (0.1,0) [0|25.4] "LPM" Vector__XXX
 SG_ DIF_criticalFlowReq : 32|1@1+ (1,0) [0|1] "" Vector__XXX
 SG_ DIF_burnInStatus : 33|3@1+ (1,0) [0|7] "" Vector__XXX

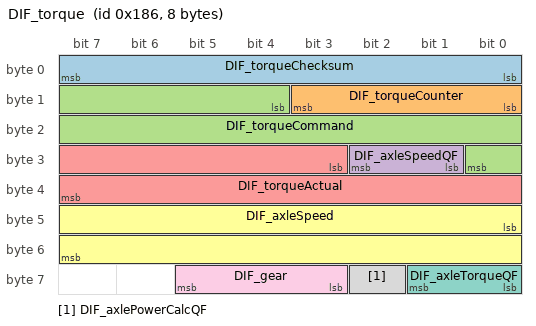
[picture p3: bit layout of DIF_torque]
BO_ 390 DIF_torque: 8 DIF
 SG_ DIF_torqueChecksum : 0|8@1+ (1,0) [0|255] "" Vector__XXX
 SG_ DIF_torqueCounter : 8|4@1+ (1,0) [0|15] "" Vector__XXX
 SG_ DIF_torqueCommand : 12|13@1- (2,0) [-7500|7500] "Nm" Vector__XXX
 SG_ DIF_axleSpeedQF : 25|2@1+ (1,0) [0|3] "" Vector__XXX
 SG_ DIF_torqueActual : 27|13@1- (2,0) [-7500|7500] "Nm" Vector__XXX
 SG_ DIF_axleSpeed : 40|16@1- (0.1,0) [-2750|2750] "RPM" Vector__XXX
 SG_ DIF_axleTorqueQF : 56|2@1+ (1,0) [0|3] "" Vector__XXX
 SG_ DIF_axlePowerCalcQF : 58|1@1+ (1,0) [0|1] "" Vector__XXX
 SG_ DIF_gear : 59|3@1+ (1,0) [0|6] "" Vector__XXX

BO_ 1557 DIF_udsResponse: 8 DIF
 SG_ DIF_udsResponseData : 7|64@0+ (1,0) [0|1.84467440737e+19] "" Vector__XXX

BO_TX_BU_ 854 : DIF;
BO_TX_BU_ 1879 : DIF;
BO_TX_BU_ 634 : DIF;
BO_TX_BU_ 1622 : DIF;
BO_TX_BU_ 421 : DIF;
BO_TX_BU_ 918 : DIF;
BO_TX_BU_ 741 : DIF;
BO_TX_BU_ 725 : DIF;
BO_TX_BU_ 886 : DIF;
BO_TX_BU_ 1367 : DIF;
BO_TX_BU_ 390 : DIF;
BO_TX_BU_ 1557 : DIF;
CM_ BO_ 854 "Front drive inverter message: alert matrix";
CM_ SG_ 854 DIF_matrixIndex "Front drive inverter: matrix index";
CM_ SG_ 854 DIF_a001_hwPhaseAgateDrive "Front drive inverter: a001 hw phase agate drive";
CM_ SG_ 854 DIF_a002_hwPhaseBgateDrive "Front drive inverter: a002 hw phase bgate drive";
CM_ SG_ 854 DIF_a003_hwPhaseCgateDrive "Front drive inverter: a003 hw phase cgate drive";
CM_ SG_ 854 DIF_a004_hwPhaseApeak "Front drive inverter: a004 hw phase apeak";
CM_ SG_ 854 DIF_a005_hwPhaseBpeak "Front drive inverter: a005 hw phase bpeak";
CM_ SG_ 854 DIF_a006_hwPhaseCpeak "Front drive inverter: a006 hw phase cpeak";
CM_ SG_ 854 DIF_a007_statorAnomalyDetected "Front drive inverter: a007 stator anomaly detected";
CM_ SG_ 854 DIF_a008_hwEncoderA "Front drive inverter: a008 hw encoder a";
CM_ SG_ 854 DIF_a009_hwEncoderB "Front drive inverter: a009 hw encoder b";
CM_ SG_ 854 DIF_a010_unintendedReset "Front drive inverter: a010 unintended reset";
CM_ SG_ 854 DIF_a011_swPowerStageNotReady "Front drive inverter: a011 sw power stage not ready";
CM_ SG_ 854 DIF_a012_hvilNotClosed "Front drive inverter: a012 hvil not closed";
CM_ SG_ 854 DIF_a013_eccError "Front drive inverter: a013 ecc error";
CM_ SG_ 854 DIF_a014_activeDamping "Front drive inverter: a014 active damping";
CM_ SG_ 854 DIF_a015_mechSafeStateAnomaly "Front drive inverter: a015 mech safe state anomaly";
CM_ SG_ 854 DIF_a016_safeStateApplied "Front drive inverter: a016 safe state applied";
CM_ SG_ 854 DIF_a017_hwPedalMonitor "Front drive inverter: a017 hw pedal monitor";
CM_ SG_ 854 DIF_a018_hwLVSupplyUV "Front drive inverter: a018 hw LV supply UV";
CM_ SG_ 854 DIF_a020_hwMotorEncoder "Front drive inverter: a020 hw motor encoder";
CM_ SG_ 854 DIF_a021_hwBusOV "Front drive inverter: a021 hw bus OV";
CM_ SG_ 854 DIF_a022_hw5vSupplyUV "Front drive inverter: a022 hw5v supply UV";
CM_ SG_ 854 DIF_a024_selfTest "Front drive inverter: a024 self test";
CM_ SG_ 854 DIF_a025_phaseApeak "Front drive inverter: a025 phase apeak";
CM_ SG_ 854 DIF_a026_phaseBpeak "Front drive inverter: a026 phase bpeak";
CM_ SG_ 854 DIF_a027_phaseCpeak "Front drive inverter: a027 phase cpeak";
CM_ SG_ 854 DIF_a028_phaseArms "Front drive inverter: a028 phase arms";
CM_ SG_ 854 DIF_a029_phaseBrms "Front drive inverter: a029 phase brms";
CM_ SG_ 854 DIF_a030_phaseCrms "Front drive inverter: a030 phase crms";
CM_ SG_ 854 DIF_a031_phaseAcurrentOffset "Front drive inverter: a031 phase acurrent offset";
CM_ SG_ 854 DIF_a032_phaseBcurrentOffset "Front drive inverter: a032 phase bcurrent offset";
CM_ SG_ 854 DIF_a033_phaseAcurrentSensor "Front drive inverter: a033 phase acurrent sensor";
CM_ SG_ 854 DIF_a034_phaseBcurrentSensor "Front drive inverter: a034 phase bcurrent sensor";
CM_ SG_ 854 DIF_a035_phaseCurrentBalance "Front drive inverter: a035 phase current balance";
CM_ SG_ 854 DIF_a036_busOV "Front drive inverter: a036 bus OV";
CM_ SG_ 854 DIF_a037_busUV "Front drive inverter: a037 bus UV";
CM_ SG_ 854 DIF_a038_busVsensor "Front drive inverter: a038 bus vsensor";
CM_ SG_ 854 DIF_a039_exceptionUndefinedInstr "Front drive inverter: a039 exception undefined instruction";
CM_ SG_ 854 DIF_a040_difMIA "Front drive inverter: a040 dif MIA";
CM_ SG_ 854 DIF_a041_sdcMIA "Front drive inverter: a041 sdc MIA";
CM_ SG_ 854 DIF_a042_inletSensor "Front drive inverter: a042 inlet sensor";
CM_ SG_ 854 DIF_a043_outletOT "Front drive inverter: a043 outlet OT";
CM_ SG_ 854 DIF_a044_outletUT "Front drive inverter: a044 outlet UT";
CM_ SG_ 854 DIF_a045_outletSensor "Front drive inverter: a045 outlet sensor";
CM_ SG_ 854 DIF_a046_statorOT "Front drive inverter: a046 stator OT";
CM_ SG_ 854 DIF_a047_statorSensor1 "Front drive inverter: a047 stator sensor1";
CM_ SG_ 854 DIF_a048_statorSensor2 "Front drive inverter: a048 stator sensor2";
CM_ SG_ 854 DIF_a049_statorSensorDiff "Front drive inverter: a049 stator sensor diff";
CM_ SG_ 854 DIF_a050_noStatorSensor "Front drive inverter: a050 no stator sensor";
CM_ SG_ 854 DIF_a052_dirMIA "Front drive inverter: a052 dir MIA";
CM_ SG_ 854 DIF_a053_unexpectedLatchState "Front drive inverter: a053 unexpected latch state";
CM_ SG_ 854 DIF_a054_driveInverterOT "Front drive inverter: a054 drive inverter OT";
CM_ SG_ 854 DIF_a055_trqCrossCheck "Front drive inverter: a055 trq cross check";
CM_ SG_ 854 DIF_a056_ambientOT "Front drive inverter: a056 ambient OT";
CM_ SG_ 854 DIF_a057_ambientUT "Front drive inverter: a057 ambient UT";
CM_ SG_ 854 DIF_a058_ambientSensor "Front drive inverter: a058 ambient sensor";
CM_ SG_ 854 DIF_a059_heatsinkOT "Front drive inverter: a059 heatsink OT";
CM_ SG_ 854 DIF_a060_heatsinkUT "Front drive inverter: a060 heatsink UT";
CM_ SG_ 854 DIF_a061_heatsinkSensor "Front drive inverter: a061 heatsink sensor";
CM_ SG_ 854 DIF_a062_systemLimpMode "Front drive inverter: a062 system limp mode";
CM_ SG_ 854 DIF_a063_bbMIA "Front drive inverter: a063 bb MIA";
CM_ SG_ 854 DIF_a064_torqueIntervention "Front drive inverter: a064 torque intervention";
CM_ SG_ 854 DIF_a065_canHardwareBusB "Front drive inverter: a065 can hardware bus b";
CM_ SG_ 854 DIF_a066_canDataBusB "Front drive inverter: a066 can data bus b";
CM_ SG_ 854 DIF_a067_canOverrunBusB "Front drive inverter: a067 can overrun bus b";
CM_ SG_ 854 DIF_a069_rotorTempLimit "Front drive inverter: a069 rotor temp limit";
CM_ SG_ 854 DIF_a070_udsTransactionInitiated "Front drive inverter: a070 uds transaction initiated";
CM_ SG_ 854 DIF_a071_busDisconnected "Front drive inverter: a071 bus disconnected";
CM_ SG_ 854 DIF_a072_gateDriveFaultCounter "Front drive inverter: a072 gate drive fault counter";
CM_ SG_ 854 DIF_a073_motorSpeed "Front drive inverter: a073 motor speed";
CM_ SG_ 854 DIF_a074_motorEncoder "Front drive inverter: a074 motor encoder";
CM_ SG_ 854 DIF_a075_motorSpeedMismatch "Front drive inverter: a075 motor speed mismatch";
CM_ SG_ 854 DIF_a076_lvSupplyOV "Front drive inverter: a076 lv supply OV";
CM_ SG_ 854 DIF_a077_lvSupplyUV "Front drive inverter: a077 lv supply UV";
CM_ SG_ 854 DIF_a078_adcRefLow "Front drive inverter: a078 adc ref low";
CM_ SG_ 854 DIF_a079_adcRefHigh "Front drive inverter: a079 adc ref high";
CM_ SG_ 854 DIF_a084_eccTestData0 "Front drive inverter: a084 ecc test data0";
CM_ SG_ 854 DIF_d085_driveInverterBoardFailu "Front drive inverter: d085 drive inverter board failure";
CM_ SG_ 854 DIF_a086_activeDischargeOn "Front drive inverter: a086 active discharge on";
CM_ SG_ 854 DIF_a087_gtwMIA "Front drive inverter: a087 gtw MIA";
CM_ SG_ 854 DIF_a088_uiMIA "Front drive inverter: a088 ui MIA";
CM_ SG_ 854 DIF_d089_invalidTorqueCommand "Front drive inverter: d089 invalid torque command";
CM_ SG_ 854 DIF_a090_pmMIA "Front drive inverter: a090 pm MIA";
CM_ SG_ 854 DIF_a091_espMIA "Front drive inverter: a091 esp MIA";
CM_ SG_ 854 DIF_a092_bmsMIA "Front drive inverter: a092 bms MIA";
CM_ SG_ 854 DIF_a093_canHardwareBusA "Front drive inverter: a093 can hardware bus a";
CM_ SG_ 854 DIF_a094_canDataBusA "Front drive inverter: a094 can data bus a";
CM_ SG_ 854 DIF_a095_canOverrunBusA "Front drive inverter: a095 can overrun bus a";
CM_ SG_ 854 DIF_a096_memoryError "Front drive inverter: a096 memory error";
CM_ SG_ 854 DIF_a097_eepromError "Front drive inverter: a097 eeprom error";
CM_ SG_ 854 DIF_a098_intTimeTooLong "Front drive inverter: a098 int time too long";
CM_ SG_ 854 DIF_a099_threadOverrun "Front drive inverter: a099 thread overrun";
CM_ SG_ 854 DIF_a100_assertion "Front drive inverter: a100 assertion";
CM_ SG_ 854 DIF_a101_eccTestData1 "Front drive inverter: a101 ecc test data1";
CM_ SG_ 854 DIF_a102_exceptionPrefetchAbort "Front drive inverter: a102 exception prefetch abort";
CM_ SG_ 854 DIF_a103_lowFlow "Front drive inverter: a103 low flow";
CM_ SG_ 854 DIF_d104_resetUnintended "Front drive inverter: d104 reset unintended";
CM_ SG_ 854 DIF_d105_busVoltageSensorIssue "Front drive inverter: d105 bus voltage sensor issue";
CM_ SG_ 854 DIF_a106_idleTaskStarving "Front drive inverter: a106 idle task starving";
CM_ SG_ 854 DIF_a107_fpgaError "Front drive inverter: a107 fpga error";
CM_ SG_ 854 DIF_a108_stateTrans "Front drive inverter: a108 state trans";
CM_ SG_ 854 DIF_a109_ahbWriteError "Front drive inverter: a109 ahb write error";
CM_ SG_ 854 DIF_a110_brakeMIA "Front drive inverter: a110 brake MIA";
CM_ SG_ 854 DIF_a111_badPhaseSensorCalib "Front drive inverter: a111 bad phase sensor calib";
CM_ SG_ 854 DIF_a112_noPhaseCurrent "Front drive inverter: a112 no phase current";
CM_ SG_ 854 DIF_a113_noFuncHeatsinkSensor "Front drive inverter: a113 no func heatsink sensor";
CM_ SG_ 854 DIF_a114_exceptionDataAbort "Front drive inverter: a114 exception data abort";
CM_ SG_ 854 DIF_a115_exceptionDataAbort2 "Front drive inverter: a115 exception data abort2";
CM_ SG_ 854 DIF_a116_highSpeedWearCounter "Front drive inverter: a116 high speed wear counter";
CM_ SG_ 854 DIF_a117_diMIA "Front drive inverter: a117 di MIA";
CM_ SG_ 854 DIF_d118_oilPumpCommsLost "Front drive inverter: d118 oil pump comms lost";
CM_ SG_ 854 DIF_a119_hvpMIA "Front drive inverter: a119 hvp MIA";
CM_ SG_ 854 DIF_a120_hvlinkMIA "Front drive inverter: a120 hvlink MIA";
CM_ SG_ 854 DIF_a121_motorControlRegulation "Front drive inverter: a121 motor control regulation";
CM_ SG_ 854 DIF_a122_highStackUsage "Front drive inverter: a122 high stack usage";
CM_ SG_ 854 DIF_a123_lossMotorControl "Front drive inverter: a123 loss motor control";
CM_ SG_ 854 DIF_d124_oilPumpServiceRequired "Front drive inverter: d124 oil pump service required";
CM_ SG_ 854 DIF_d125_currentSensorIssue "Front drive inverter: d125 current sensor issue";
CM_ SG_ 854 DIF_a126_limpMode "Front drive inverter: a126 limp mode";
CM_ SG_ 854 DIF_a127_gracefulPowerOff "Front drive inverter: a127 graceful power off";
CM_ SG_ 854 DIF_a128_fpgaVersionMismatch "Front drive inverter: a128 fpga version mismatch";
CM_ SG_ 854 DIF_d129_oilPumpIssue "Front drive inverter: d129 oil pump issue";
CM_ SG_ 854 DIF_d130_positionSensorIssue "Front drive inverter: d130 position sensor issue";
CM_ SG_ 854 DIF_d131_currentSensorOffset "Front drive inverter: d131 current sensor offset";
CM_ SG_ 854 DIF_d132_busUVIssue "Front drive inverter: d132 bus UV issue";
CM_ SG_ 854 DIF_a133_capacitorOT "Front drive inverter: a133 capacitor OT";
CM_ SG_ 854 DIF_a134_wheelSpeedIrrational "Front drive inverter: a134 wheel speed irrational";
CM_ SG_ 854 DIF_d135_rotatedStator "Front drive inverter: d135 rotated stator";
CM_ SG_ 854 DIF_a136_spiError "Front drive inverter: a136 spi error";
CM_ SG_ 854 DIF_d137_currentSensorOutOfRange "Front drive inverter: d137 current sensor out of range";
CM_ SG_ 854 DIF_d138_inverterLVPowerSupplyLo "Front drive inverter: d138 inverter LV power supply low";
CM_ SG_ 854 DIF_d141_coolingSystemIssue "Front drive inverter: d141 cooling system issue";
CM_ SG_ 854 DIF_a142_highLashAngle "Front drive inverter: a142 high lash angle";
CM_ SG_ 854 DIF_d143_wheelSpeedCorrelationIs "Front drive inverter: d143 wheel speed correlation issue";
CM_ SG_ 854 DIF_a144_configMismatch "Front drive inverter: a144 config mismatch";
CM_ SG_ 854 DIF_a147_highTorqueWearLimit "Front drive inverter: a147 high torque wear limit";
CM_ SG_ 854 DIF_a148_burnInCycleEnded "Front drive inverter: a148 burn in cycle ended";
CM_ SG_ 854 DIF_a149_oilPumpFailure "Front drive inverter: a149 oil pump failure";
CM_ SG_ 854 DIF_a150_busVD "Front drive inverter: a150 bus VD";
CM_ SG_ 854 DIF_a151_shockTorqueLimiter "Front drive inverter: a151 shock torque limiter";
CM_ SG_ 854 DIF_a152_linError "Front drive inverter: a152 lin error";
CM_ SG_ 854 DIF_a153_oilPumpDiagnostics "Front drive inverter: a153 oil pump diagnostics";
CM_ SG_ 854 DIF_a154_resolver "Front drive inverter: a154 resolver";
CM_ SG_ 854 DIF_a155_vcfrontMIA "Front drive inverter: a155 vcfront MIA";
CM_ SG_ 854 DIF_a156_currentObserver "Front drive inverter: a156 current observer";
CM_ SG_ 854 DIF_a157_rcmMIA "Front drive inverter: a157 rcm MIA";
CM_ SG_ 854 DIF_a158_ibstMIA "Front drive inverter: a158 ibst MIA";
CM_ SG_ 854 DIF_a160_busVoltageAnomaly "Front drive inverter: a160 bus voltage anomaly";
CM_ SG_ 854 DIF_a161_epas3pMIA "Front drive inverter: a161 epas3p MIA";
CM_ SG_ 854 DIF_a162_endOfLifetimeBurnIn "Front drive inverter: a162 end of lifetime burn in";
CM_ SG_ 854 DIF_d163_recoverableOvercurrent "Front drive inverter: d163 recoverable overcurrent";
CM_ SG_ 854 DIF_d164_firmwareConfigMismatch "Front drive inverter: d164 firmware config mismatch";
CM_ SG_ 854 DIF_d165_statorOverTemperature "Front drive inverter: d165 stator over temperature";
CM_ SG_ 854 DIF_d166_rotorOverTemperature "Front drive inverter: d166 rotor over temperature";
CM_ SG_ 854 DIF_d167_tempSensorIssue "Front drive inverter: d167 temp sensor issue";
CM_ SG_ 854 DIF_d168_clutchPerformance "Front drive inverter: d168 clutch performance";
CM_ SG_ 854 DIF_d169_clutchPosition "Front drive inverter: d169 clutch position";
CM_ SG_ 854 DIF_d170_clutchFailure "Front drive inverter: d170 clutch failure";
CM_ SG_ 854 DIF_a172_statorOilTempOT "Front drive inverter: a172 stator oil temp OT";
CM_ SG_ 854 DIF_a173_ascFdbkDiagnostic "Front drive inverter: a173 asc fdbk diagnostic";
CM_ SG_ 854 DIF_a174_unitMayNotRestart "Front drive inverter: a174 unit may not restart";
CM_ SG_ 854 DIF_a176_safetyICFault "Front drive inverter: a176 safety IC fault";
CM_ SG_ 854 DIF_a177_fluxReferenceCorrected "Front drive inverter: a177 flux reference corrected";
CM_ SG_ 854 DIF_a202_excessHeatUnavailable "Front drive inverter: a202 excess heat unavailable";
CM_ SG_ 854 DIF_a225_tmpEstPlausibility "Front drive inverter: a225 tmp est plausibility";
CM_ SG_ 854 DIF_a229_busVsensorOverCAN "Front drive inverter: a229 bus vsensor over CAN";
CM_ SG_ 854 DIF_a233_diMsgMissed "Front drive inverter: a233 di msg missed";
CM_ SG_ 854 DIF_a234_pcsMIA "Front drive inverter: a234 pcs MIA";
CM_ SG_ 854 DIF_a236_tasMIA "Front drive inverter: a236 tas MIA";
CM_ SG_ 854 DIF_a240_clearFusesRoutine "Front drive inverter: a240 clear fuses routine";
CM_ SG_ 854 DIF_a241_systemThermallyLimited "Front drive inverter: a241 system thermally limited";
CM_ SG_ 854 DIF_a242_spinDownLearning "Front drive inverter: a242 spin down learning";
CM_ SG_ 854 DIF_a243_ecuLogAvailable "Front drive inverter: a243 ecu log available";
CM_ SG_ 854 DIF_a244_mechSafeStateApplied "Front drive inverter: a244 mech safe state applied";
CM_ SG_ 854 DIF_a245_mechSafeStatePreWarn "Front drive inverter: a245 mech safe state pre warn";
CM_ SG_ 854 DIF_a246_recoveryAtSpeedError "Front drive inverter: a246 recovery at speed error";
CM_ SG_ 854 DIF_a247_rotorOffsetError "Front drive inverter: a247 rotor offset error";
CM_ SG_ 854 DIF_a249_highStatorTempFromResis "Front drive inverter: a249 high stator temp from resist";
CM_ SG_ 854 DIF_a250_preregulatorRail "Front drive inverter: a250 preregulator rail";
CM_ SG_ 854 DIF_a251_oilPumpService "Front drive inverter: a251 oil pump service";
CM_ SG_ 854 DIF_a252_currentCoreFallback "Front drive inverter: a252 current core fallback";
CM_ SG_ 854 DIF_a253_lvBoostedRail "Front drive inverter: a253 lv boosted rail";
CM_ SG_ 854 DIF_a254_activeDischargeRail "Front drive inverter: a254 active discharge rail";
CM_ SG_ 854 DIF_a255_currentGainFallback "Front drive inverter: a255 current gain fallback";
CM_ BO_ 1879 "Front drive inverter message: debug";
CM_ SG_ 1879 DIF_debugSelector "Front drive inverter: debug selector";
CM_ SG_ 1879 DIF_motorIA "Position from firmware; message assignment inferred.";
CM_ SG_ 1879 DIF_motorIB "Position from firmware; message assignment inferred.";
CM_ SG_ 1879 DIF_motorIC "Position from firmware; message assignment inferred.";
CM_ SG_ 1879 DIF_statorIDref "Position from firmware; message assignment inferred.";
CM_ SG_ 1879 DIF_statorIDfdb "Position from firmware; message assignment inferred.";
CM_ SG_ 1879 DIF_torquePerAmp "Position from firmware; message assignment inferred.";
CM_ SG_ 1879 DIF_rsScale "Position from firmware; message assignment inferred.";
CM_ SG_ 1879 DIF_statorIQref "Position from firmware; message assignment inferred.";
CM_ SG_ 1879 DIF_statorIQfdb "Position from firmware; message assignment inferred.";
CM_ SG_ 1879 DIF_motorV "Position from firmware; message assignment inferred.";
CM_ SG_ 1879 DIF_tqScaleDifferential "Position from firmware; message assignment inferred.";
CM_ SG_ 1879 DIF_statorFluxRef "Position from firmware; message assignment inferred.";
CM_ SG_ 1879 DIF_statorFluxFdb "Position from firmware; message assignment inferred.";
CM_ SG_ 1879 DIF_lmScale "Position from firmware; message assignment inferred.";
CM_ SG_ 1879 DIF_statorVQ "Position from firmware; message assignment inferred.";
CM_ SG_ 1879 DIF_statorVD "Position from firmware; message assignment inferred.";
CM_ SG_ 1879 DIF_peakFlux "Position from firmware; message assignment inferred.";
CM_ SG_ 1879 DIF_gainScale "Position from firmware; message assignment inferred.";
CM_ SG_ 1879 DIF_usmState "Position from firmware; message assignment inferred.";
CM_ SG_ 1879 DIF_peakIQref "Position from firmware; message assignment inferred.";
CM_ SG_ 1879 DIF_motorIAavg "Position from firmware; message assignment inferred.";
CM_ SG_ 1879 DIF_motorIBavg "Position from firmware; message assignment inferred.";
CM_ SG_ 1879 DIF_tqSatThermal "Position from firmware; message assignment inferred.";
CM_ SG_ 1879 DIF_tqSatMotorVoltage "Position from firmware; message assignment inferred.";
CM_ SG_ 1879 DIF_tqSatMotorCurrent "Position from firmware; message assignment inferred.";
CM_ SG_ 1879 DIF_tcMaxRequest "Position from firmware; message assignment inferred.";
CM_ SG_ 1879 DIF_tcMinRequest "Position from firmware; message assignment inferred.";
CM_ SG_ 1879 DIF_tqScaleMaxMotorSpeed "Position from firmware; message assignment inferred.";
CM_ SG_ 1879 DIF_wasteCurrentLimit "Position from firmware; message assignment inferred.";
CM_ SG_ 1879 DIF_llsScale "Position from firmware; message assignment inferred.";
CM_ SG_ 1879 DIF_llrScale "Position from firmware; message assignment inferred.";
CM_ SG_ 1879 DIF_oilPumpMotorSpeed "Position from firmware; message assignment inferred.";
CM_ SG_ 1879 DIF_rotorFlux "Position from firmware; message assignment inferred.";
CM_ SG_ 1879 DIF_dcCableHeat "Position from firmware; message assignment inferred.";
CM_ SG_ 1879 DIF_magnetTempEst "Position from firmware; message assignment inferred.";
CM_ SG_ 1879 DIF_resolverReady "Position from firmware; message assignment inferred.";
CM_ SG_ 1879 DIF_resolverNoCarrier "Position from firmware; message assignment inferred.";
CM_ SG_ 1879 DIF_resolverNoPhaseLock "Position from firmware; message assignment inferred.";
CM_ SG_ 1879 DIF_resolverClaMIA "Position from firmware; message assignment inferred.";
CM_ SG_ 1879 DIF_soptMaxCurrentMagSqrd "Position from firmware; message assignment inferred.";
CM_ SG_ 1879 DIF_statorVDFiltered "Position from firmware; message assignment inferred.";
CM_ SG_ 1879 DIF_statorVQFiltered "Position from firmware; message assignment inferred.";
CM_ SG_ 1879 DIF_pwmState "Position from firmware; message assignment inferred.";
CM_ SG_ 1879 DIF_dcCapTemp "Position from firmware; message assignment inferred.";
CM_ SG_ 1879 DIF_busbarTemp "Position from firmware; message assignment inferred.";
CM_ SG_ 1879 DIF_pcsTemp "Position from firmware; message assignment inferred.";
CM_ SG_ 1879 DIF_statorTemp1 "Position from firmware; message assignment inferred.";
CM_ SG_ 1879 DIF_statorTemp2 "Position from firmware; message assignment inferred.";
CM_ SG_ 1879 DIF_cpu10HzMin "Position from firmware; message assignment inferred.";
CM_ SG_ 1879 DIF_cpu10HzAvg "Position from firmware; message assignment inferred.";
CM_ SG_ 1879 DIF_cpu100HzMin "Position from firmware; message assignment inferred.";
CM_ SG_ 1879 DIF_cpu100HzAvg "Position from firmware; message assignment inferred.";
CM_ SG_ 1879 DIF_cpu10msMin "Position from firmware; message assignment inferred.";
CM_ SG_ 1879 DIF_cpu1kHzMin "Position from firmware; message assignment inferred.";
CM_ SG_ 1879 DIF_cpu1kHzAvg "Position from firmware; message assignment inferred.";
CM_ SG_ 1879 DIF_cpu20kHzMin "Position from firmware; message assignment inferred.";
CM_ SG_ 1879 DIF_cpu20kHzAvg "Position from firmware; message assignment inferred.";
CM_ SG_ 1879 DIF_hwFaultCount "Position from firmware; message assignment inferred.";
CM_ SG_ 1879 DIF_driveUnitOdometer "Position from firmware; message assignment inferred.";
CM_ SG_ 1879 DIF_phaseOutBusbarTemp "Front drive inverter: phase out busbar temp; raw 0 = signal not available (SNA)";
CM_ SG_ 1879 DIF_phaseOutBusbarWeldTemp "Front drive inverter: phase out busbar weld temp; raw 0 = signal not available (SNA)";
CM_ SG_ 1879 DIF_phaseOutLugTemp "Front drive inverter: phase out lug temp; raw 0 = signal not available (SNA)";
CM_ SG_ 1879 DIF_dcLinkCapTemp "Front drive inverter: dc link cap temp; raw 0 = signal not available (SNA)";
CM_ SG_ 1879 DIF_hvDcCableTemp "Front drive inverter: hv dc cable temp; raw 0 = signal not available (SNA)";
CM_ SG_ 1879 DIF_negDcBusbarTemp "Front drive inverter: neg dc busbar temp; raw 0 = signal not available (SNA)";
CM_ SG_ 1879 DIF_posDcBusbarTemp "Front drive inverter: pos dc busbar temp; raw 0 = signal not available (SNA)";
CM_ SG_ 1879 DIF_statorEndWindingTemp "Front drive inverter: stator end winding temp; raw 0 = signal not available (SNA)";
CM_ SG_ 1879 DIF_rotorMaxMagnetTemp "Reports the maximum temperature of the rotor magnet; raw 0 = signal not available (SNA)";
CM_ SG_ 1879 DIF_lightSenseV "Front drive inverter: light sense v";
CM_ SG_ 1879 DIF_pyroSenseV "Front drive inverter: pyro sense v";
CM_ SG_ 1879 DIF_statorSlotWindingTemp "Front drive inverter: stator slot winding temp; raw 0 = signal not available (SNA)";
CM_ SG_ 1879 DIF_intervalMaxHvBusV "Front drive inverter: interval max hv bus v";
CM_ SG_ 1879 DIF_cpu1HzMin "Position from firmware; message assignment inferred.";
CM_ SG_ 1879 DIF_cpu1HzAvg "Position from firmware; message assignment inferred.";
CM_ SG_ 1879 DIF_cpuIDWord0 "Position from firmware; message assignment inferred.";
CM_ SG_ 1879 DIF_cpuIDWord1 "Position from firmware; message assignment inferred.";
CM_ SG_ 1879 DIF_cpuIDWord2 "Position from firmware; message assignment inferred.";
CM_ SG_ 1879 DIF_cpuIDWord3 "Position from firmware; message assignment inferred.";
CM_ BO_ 634 "Front drive inverter message: hv status";
CM_ SG_ 634 DIF_hvStatusChecksum "Front drive inverter: hv status checksum";
CM_ SG_ 634 DIF_hvStatusCounter "Front drive inverter: hv status counter";
CM_ SG_ 634 DIF_hvilCurrent "HVIL Current";
CM_ SG_ 634 DIF_hvilCmVoltage "HVIL Common Mode Voltage";
CM_ SG_ 634 DIF_hvilStatus "Aggregated hardware and measured HVIL unit status; raw 3 = signal not available (SNA)";
CM_ SG_ 634 DIF_hvilSupplyState "Front drive inverter: hvil supply state";
CM_ SG_ 634 DIF_activeDischargeCtrl "Front drive inverter: active discharge ctrl";
CM_ SG_ 634 DIF_activeDischargeStatus "Active discharge status from HVIL_FAULT signal.";
CM_ SG_ 634 DIF_vBat "Reports the battery voltage measured by the Drive Inverter's local Analog to Digital Converter (ADC).";
CM_ SG_ 634 DIF_vBatQF "Front drive inverter: v bat QF";
CM_ SG_ 634 DIF_powerStageSafeState "Front drive inverter: power stage safe state";
CM_ SG_ 634 DIF_fluxState "Front drive inverter: flux state";
CM_ SG_ 634 DIF_vBusDiag "Front drive inverter: v bus diag";
CM_ SG_ 634 DIF_gateDriveState "Front drive inverter: gate drive state";
CM_ SG_ 634 DIF_gateDriveSupplyState "Front drive inverter: gate drive supply state";
CM_ BO_ 1622 "Front drive inverter message: info";
CM_ SG_ 1622 DIF_infoIndex "Front drive inverter: info index";
CM_ SG_ 1622 DIF_buildType "Front drive inverter: build type";
CM_ SG_ 1622 DIF_buildConfigurationId "Front drive inverter: build configuration id";
CM_ SG_ 1622 DIF_hardwareId "Front drive inverter: hardware id";
CM_ SG_ 1622 DIF_componentId "Front drive inverter: component id";
CM_ SG_ 1622 DIF_pcbaId "Front drive inverter: pcba id";
CM_ SG_ 1622 DIF_assemblyId "Front drive inverter: assembly id";
CM_ SG_ 1622 DIF_usageId "Front drive inverter: usage id";
CM_ SG_ 1622 DIF_subUsageId "Front drive inverter: sub usage id";
CM_ SG_ 1622 DIF_motorType "Front drive inverter: motor type; raw 0 = signal not available (SNA)";
CM_ SG_ 1622 DIF_siliconType "Front drive inverter: silicon type";
CM_ SG_ 1622 DIF_mechSafeStateType "Front drive inverter: mech safe state type; raw 0 = signal not available (SNA)";
CM_ SG_ 1622 DIF_applicationCrc "Front drive inverter: application crc";
CM_ SG_ 1622 DIF_oilPumpBuildType "Front drive inverter: oil pump build type";
CM_ SG_ 1622 DIF_oilPumpAppCrc "Front drive inverter: oil pump app crc";
CM_ SG_ 1622 DIF_FPGA_version "Front drive inverter: FPGA version; raw 255 = signal not available (SNA)";
CM_ SG_ 1622 DIF_appGitHash "Front drive inverter: app git hash";
CM_ SG_ 1622 DIF_bootGitHash "Front drive inverter: boot git hash";
CM_ SG_ 1622 DIF_platformTyp "Front drive inverter: platform typ";
CM_ SG_ 1622 DIF_infoBootLdUdsProtocolVersion "Front drive inverter: info boot ld uds protocol version";
CM_ SG_ 1622 DIF_bootloaderCrc "Front drive inverter: bootloader crc";
CM_ SG_ 1622 DIF_subcomponentGitHash "Position from firmware; message assignment inferred.";
CM_ SG_ 1622 DIF_oilPumpPcbaId "Front drive inverter: oil pump pcba id";
CM_ SG_ 1622 DIF_oilPumpAssemblyId "Front drive inverter: oil pump assembly id";
CM_ SG_ 1622 DIF_oilPumpUsageId "Front drive inverter: oil pump usage id";
CM_ SG_ 1622 DIF_refRotorFlux "Front drive inverter: ref rotor flux";
CM_ SG_ 1622 DIF_refRotorOffset "Front drive inverter: ref rotor offset; raw 2048 = signal not available (SNA)";
CM_ SG_ 1622 DIF_speedWearTotal "Front drive inverter: speed wear total; raw 255 = signal not available (SNA)";
CM_ SG_ 1622 DIF_torqueWearTotal "Front drive inverter: torque wear total; raw 255 = signal not available (SNA)";
CM_ BO_ 421 "Front drive inverter message: motor status";
CM_ SG_ 421 DIF_motorCurrent "Drive Inverer measured motor RMS phase current.";
CM_ SG_ 421 DIF_switchingFrequency "Front drive inverter: switching frequency";
CM_ SG_ 421 DIF_targetFluxMode "Front drive inverter: target flux mode";
CM_ SG_ 421 DIF_switchShortTestRetryCount "Front drive inverter: switch short test retry count";
CM_ SG_ 421 DIF_keepAliveRequest "Used to detect that the Drive Inverter (DI) expects 12V and High Voltage (HV) to be kept up in order to protect hardware.";
CM_ SG_ 421 DIF_motorStatusCounter "Front drive inverter: motor status counter";
CM_ SG_ 421 DIF_motorStatusChecksum "Front drive inverter: motor status checksum";
CM_ BO_ 918 "Front drive inverter message: oil pump";
CM_ SG_ 918 DIF_oilPumpState "Reports the state of the oil pump; raw 7 = signal not available (SNA)";
CM_ SG_ 918 DIF_oilPumpFluidTQF "Front drive inverter: oil pump fluid TQF";
CM_ SG_ 918 DIF_oilPumpLeadAngle "Front drive inverter: oil pump lead angle";
CM_ SG_ 918 DIF_oilPumpFlowTarget "Detects oil pump flow target; raw 255 = signal not available (SNA)";
CM_ SG_ 918 DIF_oilPumpFlowActual "Detects oil pump flow; raw 255 = signal not available (SNA)";
CM_ SG_ 918 DIF_oilPumpFluidT "Detects oil pump fluid tester; raw 255 = signal not available (SNA)";
CM_ SG_ 918 DIF_oilPumpPhaseCurrent "Front drive inverter: oil pump phase current; raw 255 = signal not available (SNA)";
CM_ SG_ 918 DIF_oilPumpPressureEstimate "Oil pump pressure estimate; raw 255 = signal not available (SNA)";
CM_ SG_ 918 DIF_oilPumpPressureExpected "Oil pump pressure expected; raw 255 = signal not available (SNA)";
CM_ SG_ 918 DIF_oilPumpPressureResidual "Oil pressure error outside of allowed tolerance; raw 255 = signal not available (SNA)";
CM_ BO_ 741 "Front drive inverter message: power";
CM_ SG_ 741 DIF_elecPower "Front drive inverter: elec power; raw 1024 = signal not available (SNA)";
CM_ SG_ 741 DIF_heatPowerOptimal "Front drive inverter: heat power optimal";
CM_ SG_ 741 DIF_heatPowerMax "Drive Inverter maximum heat power capability";
CM_ SG_ 741 DIF_heatPowerActual "Drive Inverter heat power";
CM_ SG_ 741 DIF_excessHeatCommand "Drive Inverter excess heat command";
CM_ SG_ 741 DIF_drivePowerMax "Front drive inverter: drive power max; raw 511 = signal not available (SNA)";
CM_ BO_ 725 "Front drive inverter message: status";
CM_ SG_ 725 DIF_statusChecksum "Front drive inverter: status checksum";
CM_ SG_ 725 DIF_statusCounter "Front drive inverter: status counter";
CM_ SG_ 725 DIF_state "DI unit state machine state.";
CM_ SG_ 725 DIF_soptState "Detects the state of the the Switch Off Path Test (SOPT); raw 8 = signal not available (SNA)";
CM_ SG_ 725 DIF_sysLimpRequest "Front drive inverter: sys limp request";
CM_ SG_ 725 DIF_softSysLimpRequest "Front drive inverter: soft sys limp request";
CM_ SG_ 725 DIF_adState "Front drive inverter: ad state";
CM_ SG_ 725 DIF_lvSupplyV "Front drive inverter: lv supply v";
CM_ SG_ 725 DIF_driveModeState "Reports the system drive mode state.";
CM_ SG_ 725 DIF_wasteState "Reports the Drive Inverter (DI) waste heat state.";
CM_ SG_ 725 DIF_haltRequest "Front drive inverter: halt request";
CM_ SG_ 725 DIF_axleSpeedLimitRequest "Front drive inverter: axle speed limit request";
CM_ SG_ 725 DIF_adDirection "Front drive inverter: ad direction";
CM_ SG_ 725 DIF_spinDownLearningState "Front drive inverter: spin down learning state";
CM_ SG_ 725 DIF_spinDownLearningMode "Front drive inverter: spin down learning mode";
CM_ BO_ 886 "Front drive inverter message: temperature";
CM_ SG_ 886 DIF_tempIndex "Front drive inverter: temp index";
CM_ SG_ 886 DIF_inverterTQF "Detects the Drive Inverter (DI) outlet temperature qualifier.";
CM_ SG_ 886 DIF_pcbT "Front drive inverter: pcb t; raw 0 = signal not available (SNA)";
CM_ SG_ 886 DIF_inverterT "Drive Inverter measured outlet temperature";
CM_ SG_ 886 DIF_statorT "Drive Inverter measured stator temperature; raw 0 = signal not available (SNA)";
CM_ SG_ 886 DIF_dcCapT "Front drive inverter: dc cap t; raw 0 = signal not available (SNA)";
CM_ SG_ 886 DIF_heatsinkT "Drive Inverter measured heatsink temperature; raw 0 = signal not available (SNA)";
CM_ SG_ 886 DIF_inverterTpct "Front drive inverter: inverter tpct";
CM_ SG_ 886 DIF_statorTpct "Front drive inverter: stator tpct";
CM_ SG_ 886 DIF_fluidInTemp "Inlet fluid temperature; raw 0 = signal not available (SNA)";
CM_ SG_ 886 DIF_normalFetBurnIn "Front drive inverter: normal fet burn in; raw 65535 = signal not available (SNA)";
CM_ SG_ 886 DIF_additionalFetBurnIn "Front drive inverter: additional fet burn in; raw 65535 = signal not available (SNA)";
CM_ SG_ 886 DIF_currentWeibullMiles "Front drive inverter: current weibull miles; raw 32767 = signal not available (SNA)";
CM_ SG_ 886 DIF_endOfServiceWeibullMiles "Front drive inverter: end of service weibull miles; raw 32767 = signal not available (SNA)";
CM_ SG_ 886 DIF_burnInDamageRatio "Front drive inverter: burn in damage ratio; raw 511 = signal not available (SNA)";
CM_ SG_ 886 DIF_inverterSensorEst "Front drive inverter: inverter sensor est";
CM_ SG_ 886 DIF_inverterHS1Est "Front drive inverter: inverter HS1 est";
CM_ SG_ 886 DIF_initialBurnInVehicleOdometer "Front drive inverter: initial burn in vehicle odometer; raw 4294967295 = signal not available (SNA)";
CM_ SG_ 886 DIF_inverterHS2Est "Front drive inverter: inverter HS2 est";
CM_ SG_ 886 DIF_inverterInletEst "Front drive inverter: inverter inlet est";
CM_ SG_ 886 DIF_statorHousingTemp "Front drive inverter: stator housing temp; raw 0 = signal not available (SNA)";
CM_ BO_ 1367 "Front drive inverter message: thermal control";
CM_ SG_ 1367 DIF_passiveInletTempReq "Front drive inverter: passive inlet temp req";
CM_ SG_ 1367 DIF_activeInletTempReq "Front drive inverter: active inlet temp req";
CM_ SG_ 1367 DIF_coolantFlowReq "Coolant flow requested";
CM_ SG_ 1367 DIF_oilFlowReq "Front drive inverter: oil flow req; raw 255 = signal not available (SNA)";
CM_ SG_ 1367 DIF_criticalFlowReq "Front drive inverter: critical flow req";
CM_ SG_ 1367 DIF_burnInStatus "Front drive inverter: burn in status";
CM_ BO_ 390 "Front drive inverter message: torque";
CM_ SG_ 390 DIF_torqueChecksum "Front drive inverter: torque checksum";
CM_ SG_ 390 DIF_torqueCounter "Front drive inverter: torque counter";
CM_ SG_ 390 DIF_torqueCommand "Torque commanded to the drive unit, referred to the axle/wheel; raw 4096 = signal not available (SNA)";
CM_ SG_ 390 DIF_axleSpeedQF "Front drive inverter: axle speed QF";
CM_ SG_ 390 DIF_torqueActual "Actual torque the drive unit is controlling to referred to the axle/wheel; raw 4096 = signal not available (SNA)";
CM_ SG_ 390 DIF_axleSpeed "Drive Inverter motor speed normalized at axle level; raw 32768 = signal not available (SNA)";
CM_ SG_ 390 DIF_axleTorqueQF "Front drive inverter: axle torque QF";
CM_ SG_ 390 DIF_axlePowerCalcQF "Front drive inverter: axle power calc QF";
CM_ SG_ 390 DIF_gear "Front drive inverter: gear; raw 7 = signal not available (SNA)";
CM_ BO_ 1557 "Front drive inverter message: uds response";
CM_ SG_ 1557 DIF_udsResponseData "Front drive inverter: uds response data";
BA_DEF_ BO_ "GenMsgCycleTime" INT 0 3600000;
BA_DEF_ BO_ "GenMsgSendType" ENUM "Cyclic","NotUsed","NotUsed","NotUsed","NotUsed","NotUsed","NotUsed","IfActive","NoMsgSendType","NotUsed";
BA_DEF_ BO_ "VFrameFormat" ENUM "StandardCAN","ExtendedCAN","reserved","J1939PG","reserved","reserved","reserved","reserved","reserved","reserved","reserved","reserved","reserved","reserved","StandardCAN_FD","ExtendedCAN_FD";
BA_DEF_ BO_ "CANFD_BRS" ENUM "0","1";
BA_DEF_ SG_ "GenSigSNA" STRING;
BA_DEF_ SG_ "SystemSignalLongSymbol" STRING;
BA_DEF_ SG_ "Confidence" ENUM "validated","plausible","layout-only","contradicted";
BA_DEF_DEF_ "GenMsgCycleTime" 0;
BA_DEF_DEF_ "GenMsgSendType" "NoMsgSendType";
BA_DEF_DEF_ "VFrameFormat" "StandardCAN";
BA_DEF_DEF_ "CANFD_BRS" "1";
BA_DEF_DEF_ "GenSigSNA" "";
BA_DEF_DEF_ "SystemSignalLongSymbol" "";
BA_DEF_DEF_ "Confidence" "layout-only";
BA_ "GenMsgCycleTime" BO_ 854 1000;
BA_ "GenMsgSendType" BO_ 854 0;
BA_ "GenMsgCycleTime" BO_ 1879 100;
BA_ "GenMsgSendType" BO_ 1879 0;
BA_ "GenMsgCycleTime" BO_ 634 100;
BA_ "GenMsgSendType" BO_ 634 0;
BA_ "GenMsgCycleTime" BO_ 1622 1000;
BA_ "GenMsgSendType" BO_ 1622 0;
BA_ "GenMsgCycleTime" BO_ 421 100;
BA_ "GenMsgSendType" BO_ 421 0;
BA_ "GenMsgCycleTime" BO_ 918 100;
BA_ "GenMsgSendType" BO_ 918 0;
BA_ "GenMsgCycleTime" BO_ 741 1000;
BA_ "GenMsgSendType" BO_ 741 0;
BA_ "GenMsgCycleTime" BO_ 725 10;
BA_ "GenMsgSendType" BO_ 725 0;
BA_ "GenMsgCycleTime" BO_ 886 1000;
BA_ "GenMsgSendType" BO_ 886 0;
BA_ "GenMsgCycleTime" BO_ 1367 1000;
BA_ "GenMsgSendType" BO_ 1367 0;
BA_ "GenMsgCycleTime" BO_ 390 10;
BA_ "GenMsgSendType" BO_ 390 0;
BA_ "Confidence" SG_ 854 DIF_matrixIndex 1;
BA_ "SystemSignalLongSymbol" SG_ 854 DIF_a039_exceptionUndefinedInstr "DIF_a039_exceptionUndefinedInstruction";
BA_ "SystemSignalLongSymbol" SG_ 854 DIF_d085_driveInverterBoardFailu "DIF_d085_driveInverterBoardFailure";
BA_ "SystemSignalLongSymbol" SG_ 854 DIF_d138_inverterLVPowerSupplyLo "DIF_d138_inverterLVPowerSupplyLow";
BA_ "SystemSignalLongSymbol" SG_ 854 DIF_d143_wheelSpeedCorrelationIs "DIF_d143_wheelSpeedCorrelationIssue";
BA_ "SystemSignalLongSymbol" SG_ 854 DIF_a249_highStatorTempFromResis "DIF_a249_highStatorTempFromResist";
BA_ "Confidence" SG_ 1879 DIF_debugSelector 1;
BA_ "Confidence" SG_ 1879 DIF_motorIA 1;
BA_ "Confidence" SG_ 1879 DIF_motorIB 1;
BA_ "Confidence" SG_ 1879 DIF_motorIC 1;
BA_ "Confidence" SG_ 1879 DIF_statorIDref 1;
BA_ "Confidence" SG_ 1879 DIF_statorIDfdb 1;
BA_ "Confidence" SG_ 1879 DIF_torquePerAmp 1;
BA_ "Confidence" SG_ 1879 DIF_rsScale 1;
BA_ "Confidence" SG_ 1879 DIF_statorIQref 1;
BA_ "Confidence" SG_ 1879 DIF_statorIQfdb 1;
BA_ "Confidence" SG_ 1879 DIF_motorV 1;
BA_ "Confidence" SG_ 1879 DIF_tqScaleDifferential 1;
BA_ "Confidence" SG_ 1879 DIF_statorFluxRef 1;
BA_ "Confidence" SG_ 1879 DIF_statorFluxFdb 1;
BA_ "Confidence" SG_ 1879 DIF_lmScale 1;
BA_ "Confidence" SG_ 1879 DIF_statorVQ 1;
BA_ "Confidence" SG_ 1879 DIF_statorVD 1;
BA_ "Confidence" SG_ 1879 DIF_peakFlux 1;
BA_ "Confidence" SG_ 1879 DIF_gainScale 1;
BA_ "Confidence" SG_ 1879 DIF_usmState 1;
BA_ "Confidence" SG_ 1879 DIF_peakIQref 1;
BA_ "Confidence" SG_ 1879 DIF_motorIAavg 1;
BA_ "Confidence" SG_ 1879 DIF_motorIBavg 1;
BA_ "Confidence" SG_ 1879 DIF_tqSatThermal 1;
BA_ "Confidence" SG_ 1879 DIF_tqSatMotorVoltage 1;
BA_ "Confidence" SG_ 1879 DIF_tqSatMotorCurrent 1;
BA_ "Confidence" SG_ 1879 DIF_tcMaxRequest 1;
BA_ "Confidence" SG_ 1879 DIF_tcMinRequest 1;
BA_ "Confidence" SG_ 1879 DIF_tqScaleMaxMotorSpeed 1;
BA_ "Confidence" SG_ 1879 DIF_wasteCurrentLimit 1;
BA_ "Confidence" SG_ 1879 DIF_llsScale 1;
BA_ "Confidence" SG_ 1879 DIF_llrScale 1;
BA_ "Confidence" SG_ 1879 DIF_oilPumpMotorSpeed 1;
BA_ "Confidence" SG_ 1879 DIF_rotorFlux 1;
BA_ "Confidence" SG_ 1879 DIF_dcCableHeat 1;
BA_ "Confidence" SG_ 1879 DIF_magnetTempEst 1;
BA_ "Confidence" SG_ 1879 DIF_resolverReady 1;
BA_ "Confidence" SG_ 1879 DIF_resolverNoCarrier 1;
BA_ "Confidence" SG_ 1879 DIF_resolverNoPhaseLock 1;
BA_ "Confidence" SG_ 1879 DIF_resolverClaMIA 1;
BA_ "Confidence" SG_ 1879 DIF_soptMaxCurrentMagSqrd 1;
BA_ "Confidence" SG_ 1879 DIF_statorVDFiltered 1;
BA_ "Confidence" SG_ 1879 DIF_statorVQFiltered 1;
BA_ "Confidence" SG_ 1879 DIF_pwmState 1;
BA_ "Confidence" SG_ 1879 DIF_dcCapTemp 1;
BA_ "Confidence" SG_ 1879 DIF_busbarTemp 1;
BA_ "Confidence" SG_ 1879 DIF_pcsTemp 1;
BA_ "Confidence" SG_ 1879 DIF_statorTemp1 1;
BA_ "Confidence" SG_ 1879 DIF_statorTemp2 1;
BA_ "Confidence" SG_ 1879 DIF_cpu10HzMin 1;
BA_ "Confidence" SG_ 1879 DIF_cpu10HzAvg 1;
BA_ "Confidence" SG_ 1879 DIF_cpu100HzMin 1;
BA_ "Confidence" SG_ 1879 DIF_cpu100HzAvg 1;
BA_ "Confidence" SG_ 1879 DIF_cpu10msMin 1;
BA_ "Confidence" SG_ 1879 DIF_cpu1kHzMin 1;
BA_ "Confidence" SG_ 1879 DIF_cpu1kHzAvg 1;
BA_ "Confidence" SG_ 1879 DIF_cpu20kHzMin 1;
BA_ "Confidence" SG_ 1879 DIF_cpu20kHzAvg 1;
BA_ "Confidence" SG_ 1879 DIF_hwFaultCount 1;
BA_ "Confidence" SG_ 1879 DIF_driveUnitOdometer 1;
BA_ "Confidence" SG_ 1879 DIF_phaseOutBusbarTemp 0;
BA_ "GenSigSNA" SG_ 1879 DIF_phaseOutBusbarTemp "0";
BA_ "Confidence" SG_ 1879 DIF_phaseOutBusbarWeldTemp 0;
BA_ "GenSigSNA" SG_ 1879 DIF_phaseOutBusbarWeldTemp "0";
BA_ "Confidence" SG_ 1879 DIF_phaseOutLugTemp 0;
BA_ "GenSigSNA" SG_ 1879 DIF_phaseOutLugTemp "0";
BA_ "Confidence" SG_ 1879 DIF_dcLinkCapTemp 0;
BA_ "GenSigSNA" SG_ 1879 DIF_dcLinkCapTemp "0";
BA_ "Confidence" SG_ 1879 DIF_hvDcCableTemp 0;
BA_ "GenSigSNA" SG_ 1879 DIF_hvDcCableTemp "0";
BA_ "Confidence" SG_ 1879 DIF_negDcBusbarTemp 0;
BA_ "GenSigSNA" SG_ 1879 DIF_negDcBusbarTemp "0";
BA_ "Confidence" SG_ 1879 DIF_posDcBusbarTemp 0;
BA_ "GenSigSNA" SG_ 1879 DIF_posDcBusbarTemp "0";
BA_ "Confidence" SG_ 1879 DIF_statorEndWindingTemp 0;
BA_ "GenSigSNA" SG_ 1879 DIF_statorEndWindingTemp "0";
BA_ "Confidence" SG_ 1879 DIF_rotorMaxMagnetTemp 0;
BA_ "GenSigSNA" SG_ 1879 DIF_rotorMaxMagnetTemp "0";
BA_ "Confidence" SG_ 1879 DIF_lightSenseV 0;
BA_ "Confidence" SG_ 1879 DIF_pyroSenseV 0;
BA_ "Confidence" SG_ 1879 DIF_statorSlotWindingTemp 0;
BA_ "GenSigSNA" SG_ 1879 DIF_statorSlotWindingTemp "0";
BA_ "Confidence" SG_ 1879 DIF_intervalMaxHvBusV 0;
BA_ "Confidence" SG_ 1879 DIF_cpu1HzMin 1;
BA_ "Confidence" SG_ 1879 DIF_cpu1HzAvg 1;
BA_ "Confidence" SG_ 1879 DIF_cpuIDWord0 1;
BA_ "Confidence" SG_ 1879 DIF_cpuIDWord1 1;
BA_ "Confidence" SG_ 1879 DIF_cpuIDWord2 1;
BA_ "Confidence" SG_ 1879 DIF_cpuIDWord3 1;
BA_ "Confidence" SG_ 634 DIF_hvStatusChecksum 0;
BA_ "Confidence" SG_ 634 DIF_hvStatusCounter 0;
BA_ "Confidence" SG_ 634 DIF_hvilCurrent 0;
BA_ "Confidence" SG_ 634 DIF_hvilCmVoltage 0;
BA_ "Confidence" SG_ 634 DIF_hvilStatus 0;
BA_ "GenSigSNA" SG_ 634 DIF_hvilStatus "3";
BA_ "Confidence" SG_ 634 DIF_hvilSupplyState 0;
BA_ "Confidence" SG_ 634 DIF_activeDischargeCtrl 0;
BA_ "Confidence" SG_ 634 DIF_activeDischargeStatus 0;
BA_ "Confidence" SG_ 634 DIF_vBat 0;
BA_ "Confidence" SG_ 634 DIF_vBatQF 0;
BA_ "Confidence" SG_ 634 DIF_powerStageSafeState 0;
BA_ "Confidence" SG_ 634 DIF_fluxState 0;
BA_ "Confidence" SG_ 634 DIF_vBusDiag 0;
BA_ "Confidence" SG_ 634 DIF_gateDriveState 0;
BA_ "Confidence" SG_ 634 DIF_gateDriveSupplyState 0;
BA_ "Confidence" SG_ 1622 DIF_infoIndex 1;
BA_ "Confidence" SG_ 1622 DIF_buildType 0;
BA_ "Confidence" SG_ 1622 DIF_buildConfigurationId 0;
BA_ "Confidence" SG_ 1622 DIF_hardwareId 0;
BA_ "Confidence" SG_ 1622 DIF_componentId 0;
BA_ "Confidence" SG_ 1622 DIF_pcbaId 0;
BA_ "Confidence" SG_ 1622 DIF_assemblyId 0;
BA_ "Confidence" SG_ 1622 DIF_usageId 0;
BA_ "Confidence" SG_ 1622 DIF_subUsageId 0;
BA_ "Confidence" SG_ 1622 DIF_motorType 0;
BA_ "GenSigSNA" SG_ 1622 DIF_motorType "0";
BA_ "Confidence" SG_ 1622 DIF_siliconType 0;
BA_ "Confidence" SG_ 1622 DIF_mechSafeStateType 0;
BA_ "GenSigSNA" SG_ 1622 DIF_mechSafeStateType "0";
BA_ "Confidence" SG_ 1622 DIF_applicationCrc 0;
BA_ "Confidence" SG_ 1622 DIF_oilPumpBuildType 0;
BA_ "Confidence" SG_ 1622 DIF_oilPumpAppCrc 0;
BA_ "Confidence" SG_ 1622 DIF_FPGA_version 0;
BA_ "GenSigSNA" SG_ 1622 DIF_FPGA_version "255";
BA_ "Confidence" SG_ 1622 DIF_appGitHash 0;
BA_ "Confidence" SG_ 1622 DIF_bootGitHash 0;
BA_ "Confidence" SG_ 1622 DIF_platformTyp 0;
BA_ "Confidence" SG_ 1622 DIF_infoBootLdUdsProtocolVersion 0;
BA_ "Confidence" SG_ 1622 DIF_bootloaderCrc 0;
BA_ "Confidence" SG_ 1622 DIF_subcomponentGitHash 1;
BA_ "Confidence" SG_ 1622 DIF_oilPumpPcbaId 0;
BA_ "Confidence" SG_ 1622 DIF_oilPumpAssemblyId 0;
BA_ "Confidence" SG_ 1622 DIF_oilPumpUsageId 0;
BA_ "Confidence" SG_ 1622 DIF_refRotorFlux 0;
BA_ "Confidence" SG_ 1622 DIF_refRotorOffset 0;
BA_ "GenSigSNA" SG_ 1622 DIF_refRotorOffset "2048";
BA_ "Confidence" SG_ 1622 DIF_speedWearTotal 0;
BA_ "GenSigSNA" SG_ 1622 DIF_speedWearTotal "255";
BA_ "Confidence" SG_ 1622 DIF_torqueWearTotal 0;
BA_ "GenSigSNA" SG_ 1622 DIF_torqueWearTotal "255";
BA_ "Confidence" SG_ 421 DIF_motorCurrent 0;
BA_ "Confidence" SG_ 421 DIF_switchingFrequency 0;
BA_ "Confidence" SG_ 421 DIF_targetFluxMode 0;
BA_ "Confidence" SG_ 421 DIF_switchShortTestRetryCount 0;
BA_ "Confidence" SG_ 421 DIF_keepAliveRequest 0;
BA_ "Confidence" SG_ 421 DIF_motorStatusCounter 0;
BA_ "Confidence" SG_ 421 DIF_motorStatusChecksum 0;
BA_ "Confidence" SG_ 918 DIF_oilPumpState 0;
BA_ "GenSigSNA" SG_ 918 DIF_oilPumpState "7";
BA_ "Confidence" SG_ 918 DIF_oilPumpFluidTQF 0;
BA_ "Confidence" SG_ 918 DIF_oilPumpLeadAngle 0;
BA_ "Confidence" SG_ 918 DIF_oilPumpFlowTarget 0;
BA_ "GenSigSNA" SG_ 918 DIF_oilPumpFlowTarget "255";
BA_ "Confidence" SG_ 918 DIF_oilPumpFlowActual 0;
BA_ "GenSigSNA" SG_ 918 DIF_oilPumpFlowActual "255";
BA_ "Confidence" SG_ 918 DIF_oilPumpFluidT 0;
BA_ "GenSigSNA" SG_ 918 DIF_oilPumpFluidT "255";
BA_ "Confidence" SG_ 918 DIF_oilPumpPhaseCurrent 0;
BA_ "GenSigSNA" SG_ 918 DIF_oilPumpPhaseCurrent "255";
BA_ "Confidence" SG_ 918 DIF_oilPumpPressureEstimate 0;
BA_ "GenSigSNA" SG_ 918 DIF_oilPumpPressureEstimate "255";
BA_ "Confidence" SG_ 918 DIF_oilPumpPressureExpected 0;
BA_ "GenSigSNA" SG_ 918 DIF_oilPumpPressureExpected "255";
BA_ "Confidence" SG_ 918 DIF_oilPumpPressureResidual 0;
BA_ "GenSigSNA" SG_ 918 DIF_oilPumpPressureResidual "255";
BA_ "Confidence" SG_ 741 DIF_elecPower 0;
BA_ "GenSigSNA" SG_ 741 DIF_elecPower "1024";
BA_ "Confidence" SG_ 741 DIF_heatPowerOptimal 0;
BA_ "Confidence" SG_ 741 DIF_heatPowerMax 0;
BA_ "Confidence" SG_ 741 DIF_heatPowerActual 0;
BA_ "Confidence" SG_ 741 DIF_excessHeatCommand 0;
BA_ "Confidence" SG_ 741 DIF_drivePowerMax 0;
BA_ "GenSigSNA" SG_ 741 DIF_drivePowerMax "511";
BA_ "Confidence" SG_ 725 DIF_statusChecksum 0;
BA_ "Confidence" SG_ 725 DIF_statusCounter 0;
BA_ "Confidence" SG_ 725 DIF_state 0;
BA_ "Confidence" SG_ 725 DIF_soptState 1;
BA_ "GenSigSNA" SG_ 725 DIF_soptState "8";
BA_ "Confidence" SG_ 725 DIF_adState 1;
BA_ "Confidence" SG_ 725 DIF_lvSupplyV 0;
BA_ "Confidence" SG_ 725 DIF_driveModeState 1;
BA_ "Confidence" SG_ 725 DIF_wasteState 1;
BA_ "Confidence" SG_ 725 DIF_haltRequest 1;
BA_ "Confidence" SG_ 725 DIF_axleSpeedLimitRequest 1;
BA_ "Confidence" SG_ 725 DIF_adDirection 1;
BA_ "Confidence" SG_ 725 DIF_spinDownLearningState 1;
BA_ "Confidence" SG_ 725 DIF_spinDownLearningMode 1;
BA_ "Confidence" SG_ 886 DIF_tempIndex 1;
BA_ "Confidence" SG_ 886 DIF_inverterTQF 0;
BA_ "Confidence" SG_ 886 DIF_pcbT 0;
BA_ "GenSigSNA" SG_ 886 DIF_pcbT "0";
BA_ "Confidence" SG_ 886 DIF_inverterT 0;
BA_ "Confidence" SG_ 886 DIF_statorT 0;
BA_ "GenSigSNA" SG_ 886 DIF_statorT "0";
BA_ "Confidence" SG_ 886 DIF_dcCapT 0;
BA_ "GenSigSNA" SG_ 886 DIF_dcCapT "0";
BA_ "Confidence" SG_ 886 DIF_heatsinkT 0;
BA_ "GenSigSNA" SG_ 886 DIF_heatsinkT "0";
BA_ "Confidence" SG_ 886 DIF_inverterTpct 0;
BA_ "Confidence" SG_ 886 DIF_statorTpct 0;
BA_ "Confidence" SG_ 886 DIF_fluidInTemp 0;
BA_ "GenSigSNA" SG_ 886 DIF_fluidInTemp "0";
BA_ "Confidence" SG_ 886 DIF_normalFetBurnIn 0;
BA_ "GenSigSNA" SG_ 886 DIF_normalFetBurnIn "65535";
BA_ "Confidence" SG_ 886 DIF_additionalFetBurnIn 0;
BA_ "GenSigSNA" SG_ 886 DIF_additionalFetBurnIn "65535";
BA_ "Confidence" SG_ 886 DIF_currentWeibullMiles 0;
BA_ "GenSigSNA" SG_ 886 DIF_currentWeibullMiles "32767";
BA_ "Confidence" SG_ 886 DIF_endOfServiceWeibullMiles 0;
BA_ "GenSigSNA" SG_ 886 DIF_endOfServiceWeibullMiles "32767";
BA_ "Confidence" SG_ 886 DIF_burnInDamageRatio 0;
BA_ "GenSigSNA" SG_ 886 DIF_burnInDamageRatio "511";
BA_ "Confidence" SG_ 886 DIF_inverterSensorEst 0;
BA_ "Confidence" SG_ 886 DIF_inverterHS1Est 0;
BA_ "Confidence" SG_ 886 DIF_initialBurnInVehicleOdometer 0;
BA_ "GenSigSNA" SG_ 886 DIF_initialBurnInVehicleOdometer "4294967295";
BA_ "Confidence" SG_ 886 DIF_inverterHS2Est 0;
BA_ "Confidence" SG_ 886 DIF_inverterInletEst 0;
BA_ "Confidence" SG_ 886 DIF_statorHousingTemp 0;
BA_ "GenSigSNA" SG_ 886 DIF_statorHousingTemp "0";
BA_ "Confidence" SG_ 1367 DIF_passiveInletTempReq 0;
BA_ "Confidence" SG_ 1367 DIF_activeInletTempReq 0;
BA_ "Confidence" SG_ 1367 DIF_coolantFlowReq 0;
BA_ "Confidence" SG_ 1367 DIF_oilFlowReq 0;
BA_ "GenSigSNA" SG_ 1367 DIF_oilFlowReq "255";
BA_ "Confidence" SG_ 1367 DIF_criticalFlowReq 0;
BA_ "Confidence" SG_ 1367 DIF_burnInStatus 0;
BA_ "Confidence" SG_ 390 DIF_torqueChecksum 0;
BA_ "Confidence" SG_ 390 DIF_torqueCounter 0;
BA_ "Confidence" SG_ 390 DIF_torqueCommand 0;
BA_ "GenSigSNA" SG_ 390 DIF_torqueCommand "4096";
BA_ "Confidence" SG_ 390 DIF_axleSpeedQF 0;
BA_ "Confidence" SG_ 390 DIF_torqueActual 0;
BA_ "GenSigSNA" SG_ 390 DIF_torqueActual "4096";
BA_ "Confidence" SG_ 390 DIF_axleSpeed 0;
BA_ "GenSigSNA" SG_ 390 DIF_axleSpeed "32768";
BA_ "Confidence" SG_ 390 DIF_axleTorqueQF 0;
BA_ "Confidence" SG_ 390 DIF_axlePowerCalcQF 0;
BA_ "Confidence" SG_ 390 DIF_gear 0;
BA_ "GenSigSNA" SG_ 390 DIF_gear "7";
BA_ "Confidence" SG_ 1557 DIF_udsResponseData 1;
VAL_ 854 DIF_matrixIndex 4 "AlertMatrix4" 3 "AlertMatrix3" 2 "AlertMatrix2" 1 "AlertMatrix1" 0 "AlertMatrix0" ;
VAL_ 1879 DIF_debugSelector 132 "Mux132" 131 "Mux131" 128 "Mux128" 73 "Mux73" 72 "Mux72" 70 "Mux70" 69 "Mux69" 68 "Mux68" 67 "Mux67" 66 "Mux66" 64 "Mux64" 63 "Mux63" 52 "Mux52" 50 "Mux50" 49 "Mux49" 48 "Mux48" 47 "Mux47" 46 "Mux46" 44 "Mux44" 43 "Mux43" 42 "Mux42" 41 "Mux41" 40 "Mux40" 39 "Mux39" 38 "Mux38" 37 "Mux37" 36 "Mux36" 35 "Mux35" 34 "Mux34" 33 "Mux33" 32 "Mux32" ;
VAL_ 1879 DIF_usmState 7 "USM_STATE_WAIT_FOR_RETRY" 6 "USM_STATE_UNAVAILABLE" 5 "USM_STATE_FAULT" 4 "USM_STATE_ENABLE" 3 "USM_STATE_ABORT" 2 "USM_STATE_RETRY" 1 "USM_STATE_STANDBY" 0 "USM_STATE_START" ;
VAL_ 1879 DIF_pwmState 3 "PWMSTATE_OPWM2" 2 "PWMSTATE_OPWM1" 1 "PWMSTATE_DPWM2" 0 "PWMSTATE_SVPWM" ;
VAL_ 1879 DIF_phaseOutBusbarTemp 0 "SNA" ;
VAL_ 1879 DIF_phaseOutBusbarWeldTemp 0 "SNA" ;
VAL_ 1879 DIF_phaseOutLugTemp 0 "SNA" ;
VAL_ 1879 DIF_dcLinkCapTemp 0 "SNA" ;
VAL_ 1879 DIF_hvDcCableTemp 0 "SNA" ;
VAL_ 1879 DIF_negDcBusbarTemp 0 "SNA" ;
VAL_ 1879 DIF_posDcBusbarTemp 0 "SNA" ;
VAL_ 1879 DIF_statorEndWindingTemp 0 "SNA" ;
VAL_ 1879 DIF_rotorMaxMagnetTemp 0 "SNA" ;
VAL_ 1879 DIF_statorSlotWindingTemp 0 "SNA" ;
VAL_ 634 DIF_hvilStatus 3 "SNA" 2 "CLOSED" 1 "OPEN" 0 "DISABLED" ;
VAL_ 634 DIF_hvilSupplyState 2 "ACTIVE" 1 "INACTIVE" 0 "NOT_AVAILABLE" ;
VAL_ 634 DIF_vBatQF 1 "QUALIFIED" 0 "NOT_QUALIFIED" ;
VAL_ 634 DIF_powerStageSafeState 3 "PSTG_SAFESTATE_3PS_LOW" 2 "PSTG_SAFESTATE_3PS_HIGH" 1 "PSTG_SAFESTATE_ALL_OFF" 0 "PSTG_SAFESTATE_NONE" ;
VAL_ 634 DIF_fluxState 12 "DI_FLUXSTATE_DISABLED" 11 "DI_FLUXSTATE_MAGNET_FLUX_DETECT" 10 "DI_FLUXSTATE_STATIONARY_WASTE" 9 "DI_FLUXSTATE_FAULT" 7 "DI_FLUXSTATE_VCONTROL" 6 "DI_FLUXSTATE_ICONTROL" 5 "DI_FLUXSTATE_ENABLED" 4 "DI_FLUXSTATE_FLUX_DOWN" 3 "DI_FLUXSTATE_FLUX_UP" 2 "DI_FLUXSTATE_STANDBY" 1 "DI_FLUXSTATE_TEST" 0 "DI_FLUXSTATE_START" ;
VAL_ 634 DIF_gateDriveState 4 "PSTG_GD_STATE_NOT_CONFIGURED" 3 "PSTG_GD_STATE_CONFIGURED" 2 "PSTG_GD_STATE_CONFIGURING" 1 "PSTG_GD_STATE_SELFTEST" 0 "PSTG_GD_STATE_INIT" ;
VAL_ 634 DIF_gateDriveSupplyState 3 "PSTG_GD_SUPPLY_FALLING" 2 "PSTG_GD_SUPPLY_UP" 1 "PSTG_GD_SUPPLY_RISING" 0 "PSTG_GD_SUPPLY_DOWN" ;
VAL_ 1622 DIF_infoIndex 255 "INFO_END" 44 "TRACKING_DATA_5" 43 "TRACKING_DATA_4" 42 "TRACKING_DATA_3" 41 "TRACKING_DATA_2" 40 "TRACKING_DATA_1" 34 "INFO_SUBCOMPONENT2_HWID" 33 "INFO_SUBCOMPONENT_HWID" 32 "INFO_SUBCOMPONENT2_GITHASH" 31 "INFO_SUBCOMPONENT_GITHASH" 23 "INFO_SUBCOMPONENT2" 20 "INFO_UDS_PROTOCOL_BOOTCRC" 19 "INFO_VERSION_DEPRECATED" 18 "INFO_BOOTLOADER_GITHASH" 17 "INFO_APP_GITHASH" 16 "INFO_SUBCOMPONENT" 15 "INFO_BOOTLOADER_CRC" 14 "INFO_BOOTLOADER_SVN" 13 "INFO_APP_CRC" 11 "INFO_PCBAID_ASSYID_USAGEID" 10 "INFO_BUILD_HWID_COMPONENTID" 9 "INFO_DEPRECATED_9" 8 "INFO_DEPRECATED_8" 7 "INFO_DEPRECATED_7" 6 "INFO_DEPRECATED_6" 5 "INFO_DEPRECATED_5" 4 "INFO_DEPRECATED_4" 3 "INFO_DEPRECATED_3" 2 "INFO_DEPRECATED_2" 1 "INFO_DEPRECATED_1" 0 "INFO_DEPRECATED_0" ;
VAL_ 1622 DIF_buildType 4 "INFO_MFG_BUILD" 3 "INFO_TRACEABLE_CI_BUILD" 2 "INFO_LOCAL_BUILD" 1 "INFO_PLATFORM_BUILD" 0 "INFO_UNKNOWN_BUILD" ;
VAL_ 1622 DIF_hardwareId 252 "CONFIGURABLE_HWID_PLACEHOLDER" ;
VAL_ 1622 DIF_motorType 36 "DI_MOTOR_PM240C" 35 "DI_MOTOR_IM188A" 34 "DI_MOTOR_IM130E_AL" 32 "DI_MOTOR_PM261D" 31 "DI_MOTOR_PM216E" 20 "DI_MOTOR_PM215D_1KV" 18 "DI_MOTOR_IM260E_1KV" 17 "DI_MOTOR_IM260D_1KV" 16 "DI_MOTOR_PM261C" 15 "DI_MOTOR_PM215C_1KV" 14 "DI_MOTOR_IM260C_1KV" 13 "DI_MOTOR_PM215A_1KV" 12 "DI_MOTOR_IM260A_1KV" 11 "DI_MOTOR_IM228HEA" 10 "DI_MOTOR_PM228HEA" 9 "DI_MOTOR_PM275C" 8 "DI_MOTOR_PM291D" 7 "DI_MOTOR_PM291C" 6 "DI_MOTOR_PM228C" 5 "DI_MOTOR_PM350B" 4 "DI_MOTOR_PM275B" 3 "DI_MOTOR_IM130D_AL" 2 "DI_MOTOR_IM130D" 1 "DI_MOTOR_PM216D" 0 "DI_MOTOR_SNA" ;
VAL_ 1622 DIF_siliconType 1 "IGBT" 0 "MOSFET" ;
VAL_ 1622 DIF_mechSafeStateType 2 "DI_MECH_SAFE_STATE_TYPE_PRESENT" 1 "DI_MECH_SAFE_STATE_TYPE_NONE" 0 "DI_MECH_SAFE_STATE_TYPE_SNA" ;
VAL_ 1622 DIF_oilPumpBuildType 4 "INFO_MFG_BUILD" 3 "INFO_TRACEABLE_CI_BUILD" 2 "INFO_LOCAL_BUILD" 1 "INFO_PLATFORM_BUILD" 0 "INFO_UNKNOWN_BUILD" ;
VAL_ 1622 DIF_FPGA_version 255 "SNA" 254 "LOCAL_BUILD" ;
VAL_ 1622 DIF_refRotorOffset -2048 "SNA" ;
VAL_ 1622 DIF_speedWearTotal 255 "SNA" ;
VAL_ 1622 DIF_torqueWearTotal 255 "SNA" ;
VAL_ 421 DIF_targetFluxMode 2 "DI_FLUXMODE_FW" 1 "DI_FLUXMODE_FS" 0 "DI_FLUXMODE_OPTIMUM" ;
VAL_ 421 DIF_keepAliveRequest 1 "KEEP_ALIVE" 0 "NO_REQUEST" ;
VAL_ 918 DIF_oilPumpState 7 "OIL_PUMP_SNA" 6 "OIL_PUMP_FAULTED" 2 "OIL_PUMP_COLD_STARTUP" 1 "OIL_PUMP_ENABLE" 0 "OIL_PUMP_STANDBY" ;
VAL_ 918 DIF_oilPumpFluidTQF 1 "OIL_PUMP_FLUIDT_HIGH_CONFIDENCE" 0 "OIL_PUMP_FLUIDT_LOW_CONFIDENCE" ;
VAL_ 918 DIF_oilPumpFlowTarget 255 "SNA" ;
VAL_ 918 DIF_oilPumpFlowActual 255 "SNA" ;
VAL_ 918 DIF_oilPumpFluidT 255 "SNA" ;
VAL_ 918 DIF_oilPumpPhaseCurrent 255 "SNA" ;
VAL_ 918 DIF_oilPumpPressureEstimate 255 "SNA" ;
VAL_ 918 DIF_oilPumpPressureExpected 255 "SNA" ;
VAL_ 918 DIF_oilPumpPressureResidual 255 "SNA" ;
VAL_ 741 DIF_elecPower -1024 "SNA" ;
VAL_ 741 DIF_drivePowerMax 511 "SNA" ;
VAL_ 725 DIF_state 4 "DI_STATE_ENABLE" 3 "DI_STATE_ABORT" 2 "DI_STATE_FAULT" 1 "DI_STATE_STANDBY" 0 "DI_STATE_UNAVAILABLE" ;
VAL_ 725 DIF_soptState 9 "SOPT_DISABLED" 8 "SOPT_SNA" 7 "SOPT_TEST_FAILED" 6 "SOPT_TEST_SKIPPED" 5 "SOPT_TEST_PASSED" 4 "SOPT_CURRENT_TEST" 3 "SOPT_ASC_TEST" 2 "SOPT_PSTG_BRING_UP_AT_SPEED" 1 "SOPT_PSTG_BRING_UP" 0 "SOPT_INIT" ;
VAL_ 725 DIF_adState 3 "AD_STATE_FAULTED" 2 "AD_STATE_BACKUP" 1 "AD_STATE_NORMAL" 0 "AD_STATE_STARTUP" ;
VAL_ 725 DIF_driveModeState 1 "DM_STATE_DRIVE" 0 "DM_STATE_NONDRIVE" ;
VAL_ 725 DIF_wasteState 3 "DI_WASTE_STATIONARY" 2 "DI_WASTE_ON" 1 "DI_WASTE_AVAILABLE" 0 "DI_WASTE_UNAVAILABLE" ;
VAL_ 725 DIF_haltRequest 2 "DI_HALT_GRACEFUL" 1 "DI_HALT_IMMEDIATE" 0 "DI_HALT_NONE" ;
VAL_ 725 DIF_adDirection 1 "AD_FORWARD" 0 "AD_BACKWARD" ;
VAL_ 725 DIF_spinDownLearningState 9 "SPINDOWN_STATE_DONE" 8 "SPINDOWN_STATE_WRITE" 7 "SPINDOWN_STATE_VERIFY" 6 "SPINDOWN_STATE_CORRECT" 5 "SPINDOWN_STATE_MEASURE" 4 "SPINDOWN_STATE_COAST" 3 "SPINDOWN_STATE_ACCELERATE" 2 "SPINDOWN_STATE_WAIT" 1 "SPINDOWN_STATE_PRECHECK" 0 "SPINDOWN_STATE_INIT" ;
VAL_ 725 DIF_spinDownLearningMode 1 "SPINDOWN_MODE_ON_GROUND" 0 "SPINDOWN_MODE_ON_LIFT" ;
VAL_ 886 DIF_tempIndex 4 "Mux4" 3 "Mux3" 2 "Mux2" 1 "Mux1" 0 "Mux0" ;
VAL_ 886 DIF_inverterTQF 3 "INVERTERT_UNKNOWN" 2 "INVERTERT_RATIONAL" 1 "INVERTERT_IRRATIONAL" 0 "INVERTERT_INIT" ;
VAL_ 886 DIF_pcbT 0 "SNA" ;
VAL_ 886 DIF_statorT 0 "SNA" ;
VAL_ 886 DIF_dcCapT 0 "SNA" ;
VAL_ 886 DIF_heatsinkT 0 "SNA" ;
VAL_ 886 DIF_fluidInTemp 0 "SNA" ;
VAL_ 886 DIF_normalFetBurnIn 65535 "SNA" ;
VAL_ 886 DIF_additionalFetBurnIn 65535 "SNA" ;
VAL_ 886 DIF_currentWeibullMiles 32767 "SNA" ;
VAL_ 886 DIF_endOfServiceWeibullMiles 32767 "SNA" ;
VAL_ 886 DIF_burnInDamageRatio 511 "SNA" 510 "DEFAULT_1" ;
VAL_ 886 DIF_initialBurnInVehicleOdometer 4294967295 "SNA" ;
VAL_ 886 DIF_statorHousingTemp 0 "SNA" ;
VAL_ 1367 DIF_oilFlowReq 255 "SNA" ;
VAL_ 1367 DIF_criticalFlowReq 1 "ACTIVE" 0 "NOT_ACTIVE" ;
VAL_ 1367 DIF_burnInStatus 5 "COMPLETE" 4 "ACTIVE" 3 "INCOMPLETE" 2 "UNAVAILABLE" 1 "NOT_REQUIRED" 0 "INIT" ;
VAL_ 390 DIF_torqueCommand -4096 "SNA" ;
VAL_ 390 DIF_axleSpeedQF 2 "FAULTED" 1 "VALID" 0 "INVALID" ;
VAL_ 390 DIF_torqueActual -4096 "SNA" ;
VAL_ 390 DIF_axleSpeed -32768 "SNA" ;
VAL_ 390 DIF_axleTorqueQF 2 "FAULTED" 1 "VALID" 0 "INVALID" ;
VAL_ 390 DIF_axlePowerCalcQF 1 "VALID" 0 "INVALID" ;
VAL_ 390 DIF_gear 7 "DI_GEAR_SNA" 4 "DI_GEAR_D" 3 "DI_GEAR_N" 2 "DI_GEAR_R" 1 "DI_GEAR_P" 0 "DI_GEAR_INVALID" ;
